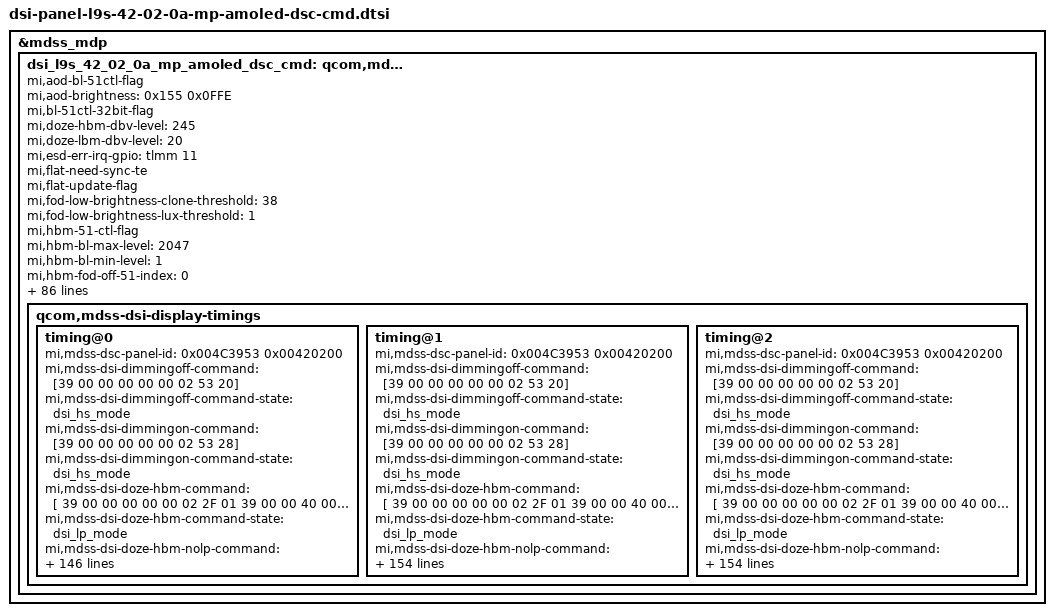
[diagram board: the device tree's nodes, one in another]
&mdss_mdp {
	dsi_l9s_42_02_0a_mp_amoled_dsc_cmd: 			qcom,mdss_dsi_l9s_42_02_0a_mp_amoled_dsc_cmd {
				mi,aod-bl-51ctl-flag;
				mi,aod-brightness = <0x155 0xffe>;
				mi,bl-51ctl-32bit-flag;
				mi,doze-hbm-dbv-level = <0xf5>;
				mi,doze-lbm-dbv-level = <0x14>;
				mi,esd-err-irq-gpio = <0xffffffff 0xb 0x2008>;
				mi,flat-need-sync-te;
				mi,flat-update-flag;
				mi,fod-low-brightness-clone-threshold = <0x26>;
				mi,fod-low-brightness-lux-threshold = <0x1>;
				mi,hbm-51-ctl-flag;
				mi,hbm-bl-max-level = <0x7ff>;
				mi,hbm-bl-min-level = <0x1>;
				mi,hbm-fod-off-51-index = <0x0>;
				mi,hbm-off-51-index = <0x0>;
				mi,local-hbm-alpha-ctrl-aa-area;
				mi,local-hbm-enabled;
				mi,local-hbm-green-500nit-update-flag;
				mi,local-hbm-white-1000nit-update-flag;
				mi,local-hbm-white-110nit-update-flag;
				mi,max-brightness-clone = <0xfff>;
				mi,mdss-dsi-fac-bl-max-level = <0x7ff>;
				mi,mdss-dsi-panel-dc-type = <0x0>;
				mi,mdss-fac-brightness-max-level = <0x7ff>;
				mi,need-fod-animal-in-normal-enabled;
				mi,panel-aod-to-off-command-need-enabled;
				mi,panel-id = <0x4c3953 0x420200>;
				mi,panel-on-dimming-delay = <0x78>;
				mi,thermal-dimming-flag;
				phandle = <0xa1>;
				qcom,bl-update-flag = "delay_until_first_frame";
				qcom,dsi-ctrl-num = <0x0>;
				qcom,dsi-phy-num = <0x0>;
				qcom,dsi-select-clocks = "pll_byte_clk0", "pll_dsi_clk0";
				qcom,esd-aod-check-enabled;
				qcom,esd-check-enabled;
				qcom,mdss-brightness-init-level = <0x133>;
				qcom,mdss-brightness-max-level = <0xfff>;
				qcom,mdss-dsi-bl-inverted-dbv;
				qcom,mdss-dsi-bl-max-level = <0xfff>;
				qcom,mdss-dsi-bl-min-level = <0x3>;
				qcom,mdss-dsi-bl-pmic-control-type = "bl_ctrl_dcs";
				qcom,mdss-dsi-bllp-eof-power-mode;
				qcom,mdss-dsi-bllp-power-mode;
				qcom,mdss-dsi-border-color = <0x0>;
				qcom,mdss-dsi-bpp = <0x1e>;
				qcom,mdss-dsi-clk-strength = <0xff>;
				qcom,mdss-dsi-color-order = "rgb_swap_rgb";
				qcom,mdss-dsi-dma-schedule-line = <0x1>;
				qcom,mdss-dsi-dma-schedule-window = <0x32>;
				qcom,mdss-dsi-dma-trigger = "trigger_sw";
				qcom,mdss-dsi-factory-bl-max-level = <0x7ff>;
				qcom,mdss-dsi-lane-0-state;
				qcom,mdss-dsi-lane-1-state;
				qcom,mdss-dsi-lane-2-state;
				qcom,mdss-dsi-lane-3-state;
				qcom,mdss-dsi-lane-map = "lane_map_0123";
				qcom,mdss-dsi-lp11-init;
				qcom,mdss-dsi-mdp-trigger = "none";
				qcom,mdss-dsi-panel-blackness-level = <0xc9e>;
				qcom,mdss-dsi-panel-hdr-color-primaries = <0x38a4 0x3c8c 0x7d00 0x4268 0x3c8c 0x7530 0x1f40 0xbb8>;
				qcom,mdss-dsi-panel-hdr-enabled;
				qcom,mdss-dsi-panel-mode-switch;
				qcom,mdss-dsi-panel-name = "xiaomi 42 02 0a cmd mode dsc dsi panel";
				qcom,mdss-dsi-panel-peak-brightness = <0x401640>;
				qcom,mdss-dsi-panel-status-check-mode = "reg_read";
				qcom,mdss-dsi-panel-status-command = <0x6010000 0x1fa>;
				qcom,mdss-dsi-panel-status-command-state = "dsi_lp_mode";
				qcom,mdss-dsi-panel-status-offset-command = [39 01 00 00 00 00 05 ff aa 55 a5 81 15 01 00 00 00 00 02 6f 0f];
				qcom,mdss-dsi-panel-status-offset-command-state = "dsi_lp_mode";
				qcom,mdss-dsi-panel-status-read-length = <0x1>;
				qcom,mdss-dsi-panel-status-value = <0x0>;
				qcom,mdss-dsi-panel-type = "dsi_cmd_mode";
				qcom,mdss-dsi-reset-sequence = <0x1 0xb 0x0 0x1 0x1 0xb>;
				qcom,mdss-dsi-stream = <0x0>;
				qcom,mdss-dsi-te-check-enable;
				qcom,mdss-dsi-te-dcs-command = <0x1>;
				qcom,mdss-dsi-te-pin-select = <0x1>;
				qcom,mdss-dsi-te-using-te-pin;
				qcom,mdss-dsi-traffic-mode = "burst_mode";
				qcom,mdss-dsi-tx-eot-append;
				qcom,mdss-dsi-underflow-color = <0xff>;
				qcom,mdss-dsi-virtual-channel-id = <0x0>;
				qcom,mdss-dsi-wr-mem-continue = <0x3c>;
				qcom,mdss-dsi-wr-mem-start = <0x2c>;
				qcom,mdss-factory-brightness-max-level = <0x7ff>;
				qcom,mdss-pan-physical-height-dimension = <0x5ed>;
				qcom,mdss-pan-physical-width-dimension = <0x2ab>;
				qcom,panel-supply-entries = <0x8b>;
				qcom,platform-reset-gpio = <0xffffffff 0x2a 0x0>;
				qcom,platform-te-gpio = <0xffffffff 0x52 0x0>;

				qcom,mdss-dsi-display-timings {

					timing@0 {
						mi,mdss-dsc-panel-id = <0x4c3953 0x420200>;
						mi,mdss-dsi-dimmingoff-command = [39 00 00 00 00 00 02 53 20];
						mi,mdss-dsi-dimmingoff-command-state = "dsi_hs_mode";
						mi,mdss-dsi-dimmingon-command = [39 00 00 00 00 00 02 53 28];
						mi,mdss-dsi-dimmingon-command-state = "dsi_hs_mode";
						mi,mdss-dsi-doze-hbm-command = [39 00 00 00 00 00 02 2f 01 39 00 00 40 00 00 02 26 01 39 00 00 40 00 00 06 f0 55 aa 52 08 00 39 00 00 40 00 00 02 b2 08 39 00 00 40 00 00 05 51 00 f5 0f fe 39 00 00 00 00 00 02 39 00];
						mi,mdss-dsi-doze-hbm-command-state = "dsi_lp_mode";
						mi,mdss-dsi-doze-hbm-nolp-command = [39 00 00 00 00 00 06 f0 55 aa 52 08 00 39 00 00 40 00 00 02 b2 18 39 00 00 40 00 00 05 51 00 f5 0f fe 39 00 00 00 00 00 02 38 00];
						mi,mdss-dsi-doze-hbm-nolp-command-state = "dsi_lp_mode";
						mi,mdss-dsi-doze-lbm-command = [39 00 00 00 00 00 02 2f 01 39 00 00 40 00 00 02 26 01 39 00 00 40 00 00 06 f0 55 aa 52 08 00 39 00 00 40 00 00 02 b2 08 39 00 00 40 00 00 05 51 00 14 01 55 39 00 00 00 00 00 02 39 00];
						mi,mdss-dsi-doze-lbm-command-state = "dsi_lp_mode";
						mi,mdss-dsi-doze-lbm-nolp-command = [39 00 00 00 00 00 06 f0 55 aa 52 08 00 39 00 00 40 00 00 02 b2 18 39 00 00 40 00 00 05 51 00 14 01 55 39 00 00 00 00 00 02 38 00];
						mi,mdss-dsi-doze-lbm-nolp-command-state = "dsi_lp_mode";
						mi,mdss-dsi-flat-mode-off-command = <0x39000000 0x22f 0x1390000 0x40000002 0x26013900 0x400000 0x6f055aa 0x52080839 0x4000 0x26f07 0x39000020 0x5b9 0x18>;
						mi,mdss-dsi-flat-mode-off-command-state = "dsi_lp_mode";
						mi,mdss-dsi-flat-mode-off-command-update = <0xb9 0x4 0x4>;
						mi,mdss-dsi-flat-mode-off-read-pre-command = [39 00 00 00 00 00 06 f0 55 aa 52 08 00 39 00 00 00 00 00 02 6f 48];
						mi,mdss-dsi-flat-mode-off-read-pre-command-state = "dsi_lp_mode";
						mi,mdss-dsi-flat-mode-on-command = <0x39000000 0x22f 0x1390000 0x40000002 0x26043900 0x400000 0x6f055aa 0x52080839 0x4000 0x26f07 0x39000020 0x5b9 0x0>;
						mi,mdss-dsi-flat-mode-on-command-state = "dsi_lp_mode";
						mi,mdss-dsi-flat-mode-on-command-update = <0xb9 0x4 0x4>;
						mi,mdss-dsi-flat-mode-read-pre-command = [39 00 00 00 00 00 06 f0 55 aa 52 08 00 39 00 00 00 00 00 02 6f 3f];
						mi,mdss-dsi-flat-mode-read-pre-command-state = "dsi_lp_mode";
						mi,mdss-dsi-hbm-off-command = <0x39000000 0x551 0x7ff0000>;
						mi,mdss-dsi-hbm-off-command-state = "dsi_lp_mode";
						mi,mdss-dsi-hbm-on-command = <0x39000000 0x551 0xfff0000>;
						mi,mdss-dsi-hbm-on-command-state = "dsi_lp_mode";
						mi,mdss-dsi-local-hbm-hlpm-white-1000nit-command = [39 00 00 00 00 00 06 f0 55 aa 52 08 00 39 00 00 40 00 00 02 b2 18 39 00 00 40 00 00 02 38 00 39 00 00 40 00 00 06 f0 55 aa 52 08 00 39 00 00 40 00 00 02 6f 29 39 00 00 40 00 00 02 d9 00 39 00 00 40 00 00 02 6f 01 39 00 00 40 00 00 02 d9 80 39 00 00 40 00 00 02 6f 07 39 00 00 40 00 00 03 b2 07 ff 39 00 00 40 00 00 02 6f 17 39 00 00 40 00 00 03 b2 07 ff 39 00 00 40 00 00 02 6f 1f 39 00 00 40 00 00 03 b2 00 50 39 00 00 40 00 00 06 f0 55 aa 52 08 02 39 00 00 40 00 00 02 6f 08 39 00 00 40 00 00 07 d0 0b 07 09 7b 0c 1d 39 00 00 40 00 00 06 f0 55 aa 52 08 07 39 00 00 40 00 00 02 c0 05 39 00 00 40 00 00 02 53 20 39 00 00 40 00 00 05 88 02 1c 08 73 39 00 00 40 00 00 03 51 07 ff 39 00 00 40 00 00 03 87 04 4e 39 00 00 40 00 00 02 6f 02 39 00 00 00 30 00 02 87 05];
						mi,mdss-dsi-local-hbm-hlpm-white-1000nit-command-state = "dsi_hs_mode";
						mi,mdss-dsi-local-hbm-hlpm-white-1000nit-command-update = <0x87 0x16 0x2 0xd0 0x10 0x6>;
						mi,mdss-dsi-local-hbm-hlpm-white-110nit-command = [39 00 00 00 00 00 06 f0 55 aa 52 08 00 39 00 00 40 00 00 02 b2 18 39 00 00 40 00 00 02 38 00 39 00 00 40 00 00 06 f0 55 aa 52 08 00 39 00 00 40 00 00 02 6f 29 39 00 00 40 00 00 02 d9 00 39 00 00 40 00 00 02 6f 01 39 00 00 40 00 00 02 d9 80 39 00 00 40 00 00 02 6f 07 39 00 00 40 00 00 03 b2 07 ff 39 00 00 40 00 00 02 6f 17 39 00 00 40 00 00 03 b2 07 ff 39 00 00 40 00 00 02 6f 1f 39 00 00 40 00 00 03 b2 00 50 39 00 00 40 00 00 06 f0 55 aa 52 08 02 39 00 00 40 00 00 02 6f 08 39 00 00 40 00 00 07 d0 0b 07 09 7b 0c 1d 39 00 00 40 00 00 06 f0 55 aa 52 08 07 39 00 00 40 00 00 02 c0 05 39 00 00 40 00 00 02 53 20 39 00 00 40 00 00 05 88 02 1c 08 73 39 00 00 40 00 00 03 51 07 ff 39 00 00 40 00 00 03 87 04 4e 39 00 00 40 00 00 02 6f 02 39 00 00 00 30 00 02 87 05];
						mi,mdss-dsi-local-hbm-hlpm-white-110nit-command-state = "dsi_hs_mode";
						mi,mdss-dsi-local-hbm-hlpm-white-110nit-command-update = <0x87 0x16 0x2 0xd0 0x10 0x6>;
						mi,mdss-dsi-local-hbm-normal-green-500nit-command = [39 00 00 00 00 00 06 f0 55 aa 52 08 00 39 00 00 40 00 00 02 6f 29 39 00 00 40 00 00 02 d9 00 39 00 00 40 00 00 02 6f 01 39 00 00 40 00 00 02 d9 80 39 00 00 40 00 00 02 6f 07 39 00 00 40 00 00 03 b2 07 ff 39 00 00 40 00 00 02 6f 17 39 00 00 40 00 00 03 b2 07 ff 39 00 00 40 00 00 02 6f 1f 39 00 00 40 00 00 03 b2 00 50 39 00 00 40 00 00 06 f0 55 aa 52 08 02 39 00 00 40 00 00 02 6f 08 39 00 00 40 00 00 07 d0 00 00 09 40 00 00 39 00 00 40 00 00 06 f0 55 aa 52 08 07 39 00 00 40 00 00 02 c0 05 39 00 00 40 00 00 02 53 20 39 00 00 40 00 00 05 88 02 1c 08 73 39 00 00 40 00 00 03 51 07 ff 39 00 00 40 00 00 03 87 04 4e 39 00 00 40 00 00 02 6f 02 39 00 00 00 30 00 02 87 05];
						mi,mdss-dsi-local-hbm-normal-green-500nit-command-state = "dsi_hs_mode";
						mi,mdss-dsi-local-hbm-normal-green-500nit-command-update = <0x87 0x13 0x2 0xd0 0xd 0x6>;
						mi,mdss-dsi-local-hbm-normal-white-1000nit-command = [39 00 00 00 00 00 06 f0 55 aa 52 08 00 39 00 00 40 00 00 02 6f 29 39 00 00 40 00 00 02 d9 00 39 00 00 40 00 00 02 6f 01 39 00 00 40 00 00 02 d9 80 39 00 00 40 00 00 02 6f 07 39 00 00 40 00 00 03 b2 07 ff 39 00 00 40 00 00 02 6f 17 39 00 00 40 00 00 03 b2 07 ff 39 00 00 40 00 00 02 6f 1f 39 00 00 40 00 00 03 b2 00 50 39 00 00 40 00 00 06 f0 55 aa 52 08 02 39 00 00 40 00 00 02 6f 08 39 00 00 40 00 00 07 d0 0b 07 09 7b 0c 1d 39 00 00 40 00 00 06 f0 55 aa 52 08 07 39 00 00 40 00 00 02 c0 05 39 00 00 40 00 00 02 53 20 39 00 00 40 00 00 05 88 02 1c 08 73 39 00 00 40 00 00 03 51 07 ff 39 00 00 40 00 00 03 87 04 4e 39 00 00 40 00 00 02 6f 02 39 00 00 00 30 00 02 87 05];
						mi,mdss-dsi-local-hbm-normal-white-1000nit-command-state = "dsi_hs_mode";
						mi,mdss-dsi-local-hbm-normal-white-1000nit-command-update = <0x87 0x13 0x2 0xd0 0xd 0x6>;
						mi,mdss-dsi-local-hbm-normal-white-110nit-command = [39 00 00 00 00 00 06 f0 55 aa 52 08 00 39 00 00 40 00 00 02 6f 29 39 00 00 40 00 00 02 d9 00 39 00 00 40 00 00 02 6f 01 39 00 00 40 00 00 02 d9 80 39 00 00 40 00 00 02 6f 07 39 00 00 40 00 00 03 b2 07 ff 39 00 00 40 00 00 02 6f 17 39 00 00 40 00 00 03 b2 07 ff 39 00 00 40 00 00 02 6f 1f 39 00 00 40 00 00 03 b2 00 50 39 00 00 40 00 00 06 f0 55 aa 52 08 02 39 00 00 40 00 00 02 6f 08 39 00 00 40 00 00 07 d0 0b 07 09 7b 0c 1d 39 00 00 40 00 00 06 f0 55 aa 52 08 07 39 00 00 40 00 00 02 c0 05 39 00 00 40 00 00 02 53 20 39 00 00 40 00 00 05 88 02 1c 08 73 39 00 00 40 00 00 03 51 07 ff 39 00 00 40 00 00 03 87 04 4e 39 00 00 40 00 00 02 6f 02 39 00 00 00 30 00 02 87 05];
						mi,mdss-dsi-local-hbm-normal-white-110nit-command-state = "dsi_hs_mode";
						mi,mdss-dsi-local-hbm-normal-white-110nit-command-update = <0x87 0x13 0x2 0xd0 0xd 0x6>;
						mi,mdss-dsi-local-hbm-off-to-hbm-command = [39 00 00 00 00 00 02 53 20 39 00 00 40 00 00 03 51 00 00 39 00 00 40 00 00 02 6f 02 39 00 00 00 00 00 02 87 04];
						mi,mdss-dsi-local-hbm-off-to-hbm-command-state = "dsi_hs_mode";
						mi,mdss-dsi-local-hbm-off-to-hbm-command-update = <0x51 0x1 0x2>;
						mi,mdss-dsi-local-hbm-off-to-hlpm-command = [39 00 00 00 00 00 02 53 20 39 00 00 40 00 00 03 51 00 00 39 00 00 40 00 00 02 6f 02 39 00 00 40 00 00 02 87 04 39 00 00 40 00 00 02 2f 01 39 00 00 40 00 00 02 26 01 39 00 00 40 00 00 06 f0 55 aa 52 08 00 39 00 00 40 00 00 02 b2 08 39 00 00 40 00 00 05 51 00 f5 0f ff 39 00 00 00 00 00 02 39 00];
						mi,mdss-dsi-local-hbm-off-to-hlpm-command-state = "dsi_hs_mode";
						mi,mdss-dsi-local-hbm-off-to-llpm-command = [39 00 00 00 00 00 02 53 20 39 00 00 40 00 00 03 51 00 00 39 00 00 40 00 00 02 6f 02 39 00 00 40 00 00 02 87 04 39 00 00 40 00 00 02 2f 01 39 00 00 40 00 00 02 26 01 39 00 00 40 00 00 06 f0 55 aa 52 08 00 39 00 00 40 00 00 02 b2 08 39 00 00 40 00 00 05 51 00 14 01 55 39 00 00 00 00 00 02 39 00];
						mi,mdss-dsi-local-hbm-off-to-llpm-command-state = "dsi_hs_mode";
						mi,mdss-dsi-local-hbm-off-to-normal-command = [39 00 00 00 00 00 02 53 20 39 00 00 40 00 00 03 51 00 00 39 00 00 40 00 00 02 6f 02 39 00 00 00 00 00 02 87 04];
						mi,mdss-dsi-local-hbm-off-to-normal-command-state = "dsi_hs_mode";
						mi,mdss-dsi-local-hbm-off-to-normal-command-update = <0x51 0x1 0x2>;
						mi,mdss-dsi-pre-doze-to-off-command = [39 01 00 00 00 00 06 f0 55 aa 52 08 01 39 01 00 00 00 00 02 ce 0c];
						mi,mdss-dsi-pre-doze-to-off-command-state = "dsi_hs_mode";
						mi,mdss-dsi-switch-page-command = [39 00 00 00 00 00 06 f0 55 aa 52 08 00];
						mi,mdss-dsi-switch-page-command-state = "dsi_lp_mode";
						mi,mdss-dsi-switch-page-command-update = <0xf0 0x0 0x5>;
						mi,mdss-flat-status-control-gamma-cfg = <0x4 0x1>;
						qcom,compression-mode = "dsc";
						qcom,default-topology-index = <0x0>;
						qcom,display-topology = <0x1 0x1 0x1>;
						qcom,mdss-dsc-bit-per-component = <0xa>;
						qcom,mdss-dsc-bit-per-pixel = <0x8>;
						qcom,mdss-dsc-block-prediction-enable;
						qcom,mdss-dsc-scr-version = <0x0>;
						qcom,mdss-dsc-slice-height = <0xc>;
						qcom,mdss-dsc-slice-per-pkt = <0x1>;
						qcom,mdss-dsc-slice-width = <0x438>;
						qcom,mdss-dsc-version = <0x11>;
						qcom,mdss-dsi-cmd-mode;
						qcom,mdss-dsi-h-back-porch = <0x40>;
						qcom,mdss-dsi-h-front-porch = <0x20>;
						qcom,mdss-dsi-h-left-border = <0x0>;
						qcom,mdss-dsi-h-pulse-width = <0x40>;
						qcom,mdss-dsi-h-right-border = <0x0>;
						qcom,mdss-dsi-h-sync-pulse = <0x0>;
						qcom,mdss-dsi-h-sync-skew = <0x0>;
						qcom,mdss-dsi-nolp-command = [39 00 00 00 00 00 06 f0 55 aa 52 08 00 39 00 00 40 00 00 02 b2 18 39 00 00 00 32 00 02 38 00];
						qcom,mdss-dsi-nolp-command-state = "dsi_hs_mode";
						qcom,mdss-dsi-off-command = [39 00 00 00 0a 00 02 28 00 39 00 00 00 78 00 02 10 00];
						qcom,mdss-dsi-off-command-state = "dsi_lp_mode";
						qcom,mdss-dsi-on-command = [39 00 00 00 00 00 06 f0 55 aa 52 08 00 39 00 00 40 00 00 02 6f 08 39 00 00 40 00 00 09 ba 01 b1 00 0a 00 16 00 00 39 00 00 40 00 00 06 f0 55 aa 52 08 04 39 00 00 40 00 00 02 b1 02 39 00 00 40 00 00 05 3b 00 14 00 0c 39 00 00 40 00 00 02 90 01 39 00 00 40 00 00 13 91 ab 28 00 0c c2 00 03 1c 01 7e 00 0f 08 bb 04 3d 10 f0 39 00 00 40 00 00 02 03 01 39 00 00 40 00 00 02 2c 00 39 00 00 40 00 00 06 f0 55 aa 52 08 07 39 00 00 40 00 00 02 c0 05 39 00 00 40 00 00 02 c1 00 39 00 00 40 00 00 02 c2 00 39 00 00 40 00 00 02 c3 00 39 00 00 40 00 00 02 c4 00 39 00 00 40 00 00 02 c5 00 39 00 00 40 00 00 02 c6 00 39 00 00 40 00 00 02 c7 00 39 00 00 40 00 00 02 c8 00 39 00 00 40 00 00 02 cd 00 39 00 00 40 00 00 02 ce 00 39 00 00 40 00 00 02 cf 00 39 00 00 40 00 00 02 d0 00 39 00 00 40 00 00 02 53 20 39 00 00 40 00 00 06 f0 55 aa 52 08 00 39 00 00 40 00 00 02 6f 02 39 00 00 40 00 00 03 b2 08 08 39 00 00 40 00 00 02 35 00 39 00 00 40 00 00 06 f0 55 aa 52 08 01 39 00 00 40 00 00 08 c3 94 01 8c d0 22 02 00 39 00 00 40 00 00 05 2a 00 00 04 37 39 00 00 40 00 00 05 2b 00 00 09 5f 39 00 00 40 00 00 02 2f 01 39 00 00 40 00 00 02 26 01 39 00 00 40 00 00 06 f0 55 aa 52 08 00 39 00 00 40 00 00 02 6f 05 39 00 00 00 00 00 02 be 88 39 00 00 40 00 00 05 ff aa 55 a5 80 39 00 00 40 00 00 02 6f 61 39 00 00 40 00 00 02 f3 80 39 00 00 40 00 00 06 f0 55 aa 52 08 01 39 00 00 40 00 00 02 6f 01 39 00 00 40 00 00 04 d2 00 00 11 39 00 00 40 00 00 02 6f 06 39 00 00 40 00 00 02 d2 05 39 00 00 40 00 00 02 6f 0f 39 00 00 40 00 00 02 d2 00 39 00 00 40 00 00 02 6f 09 39 00 00 00 00 00 03 d2 00 00 39 00 00 40 00 00 06 f0 55 aa 52 08 00 39 00 00 40 00 00 02 6f 01 39 00 00 40 00 00 02 c0 b3 39 00 00 40 00 00 05 ff aa 55 a5 80 39 00 00 40 00 00 02 6f 2e 39 00 00 40 00 00 02 fb d1 39 00 00 40 00 00 06 f0 55 aa 52 08 04 39 00 00 40 00 00 02 6f 0d 39 00 00 00 00 00 02 ca 05 39 00 00 40 00 00 06 f0 55 aa 52 08 07 39 00 00 40 00 00 02 c0 05 39 00 00 40 00 00 02 6f 00 39 00 00 40 00 00 16 c9 21 00 21 c9 21 10 00 00 3f e7 b7 88 3f e7 fa 60 80 04 5d 05 90 39 00 00 40 00 00 02 6f 15 39 00 00 40 00 00 10 c9 81 c0 16 82 1c 73 33 a0 21 6c 0f a3 a4 00 00 39 00 00 40 00 00 02 6f 24 39 00 00 40 00 00 08 c9 00 00 00 00 00 00 00 39 00 00 40 00 00 02 6f 00 39 00 00 40 00 00 16 ca 27 00 21 c9 21 10 00 00 00 00 00 00 3f e7 fa 60 80 00 00 00 00 39 00 00 40 00 00 02 6f 15 39 00 00 40 00 00 10 ca 82 1d 16 82 79 73 33 a0 00 00 03 5d a4 00 00 39 00 00 40 00 00 02 6f 24 39 00 00 40 00 00 08 ca 00 00 00 00 00 00 00 39 00 00 40 00 00 02 6f 00 39 00 00 40 00 00 16 cb 2d 00 21 10 21 10 00 00 3f e8 3c 80 80 00 00 00 00 00 00 00 00 39 00 00 40 00 00 02 6f 15 39 00 00 40 00 00 10 cb 81 c0 74 82 1c d0 33 10 00 00 0c a4 5c 00 00 39 00 00 40 00 00 02 6f 24 39 00 00 40 00 00 08 cb 00 00 00 00 00 00 00 39 00 00 40 00 00 02 6f 00 39 00 00 40 00 00 16 cc 2b 00 21 10 21 10 00 00 00 00 00 00 80 00 00 00 7f fb ba df 00 39 00 00 40 00 00 02 6f 15 39 00 00 40 00 00 10 cc 82 1d 74 82 79 d0 33 1f de f0 00 5c 5c 00 00 39 00 00 40 00 00 02 6f 24 39 00 00 00 00 00 08 cc 00 00 00 00 00 00 00 39 00 00 40 00 00 06 f0 55 aa 52 08 01 39 00 00 00 00 00 07 b7 20 20 20 20 20 20 39 00 00 00 50 00 02 11 00 39 00 00 00 00 00 02 29 00];
						qcom,mdss-dsi-on-command-state = "dsi_lp_mode";
						qcom,mdss-dsi-panel-clockrate = <0x31880dc0>;
						qcom,mdss-dsi-panel-framerate = <0x3c>;
						qcom,mdss-dsi-panel-height = <0x960>;
						qcom,mdss-dsi-panel-jitter = <0x5 0x1>;
						qcom,mdss-dsi-panel-phy-timings = [00 1d 07 07 17 22 07 07 08 02 04 00 19 0c];
						qcom,mdss-dsi-panel-width = <0x438>;
						qcom,mdss-dsi-timing-switch-command = <0x39000000 0x6f0 0x55aa5208 0x2390000 0x40000002 0xcc003900 0x400000 0x22f0139 0x0 0x22601>;
						qcom,mdss-dsi-timing-switch-command-state = "dsi_hs_mode";
						qcom,mdss-dsi-timing-switch-command-update = <0x26 0x3 0x1>;
						qcom,mdss-dsi-v-back-porch = <0x254>;
						qcom,mdss-dsi-v-bottom-border = <0x0>;
						qcom,mdss-dsi-v-front-porch = <0x3e8>;
						qcom,mdss-dsi-v-pulse-width = <0x7e>;
						qcom,mdss-dsi-v-top-border = <0x0>;
						qcom,mdss-mdp-transfer-time-us = <0x36b0>;
					};

					timing@1 {
						mi,mdss-dsc-panel-id = <0x4c3953 0x420200>;
						mi,mdss-dsi-dimmingoff-command = [39 00 00 00 00 00 02 53 20];
						mi,mdss-dsi-dimmingoff-command-state = "dsi_hs_mode";
						mi,mdss-dsi-dimmingon-command = [39 00 00 00 00 00 02 53 28];
						mi,mdss-dsi-dimmingon-command-state = "dsi_hs_mode";
						mi,mdss-dsi-doze-hbm-command = [39 00 00 00 00 00 02 2f 01 39 00 00 40 00 00 02 26 01 39 00 00 40 00 00 06 f0 55 aa 52 08 00 39 00 00 40 00 00 02 b2 08 39 00 00 40 00 00 05 51 00 f5 0f fe 39 00 00 00 00 00 02 39 00];
						mi,mdss-dsi-doze-hbm-command-state = "dsi_lp_mode";
						mi,mdss-dsi-doze-hbm-nolp-command = <0x39000000 0x6f0 0x55aa5208 0x390000 0x40000002 0xb2183900 0x400000 0x55100f5 0xffe3900 0x0 0x2380039 0x0 0x22f02>;
						mi,mdss-dsi-doze-hbm-nolp-command-state = "dsi_lp_mode";
						mi,mdss-dsi-doze-lbm-command = [39 00 00 00 00 00 02 2f 01 39 00 00 40 00 00 02 26 01 39 00 00 40 00 00 06 f0 55 aa 52 08 00 39 00 00 40 00 00 02 b2 08 39 00 00 40 00 00 05 51 00 14 01 55 39 00 00 00 00 00 02 39 00];
						mi,mdss-dsi-doze-lbm-command-state = "dsi_lp_mode";
						mi,mdss-dsi-doze-lbm-nolp-command = <0x39000000 0x6f0 0x55aa5208 0x390000 0x40000002 0xb2183900 0x400000 0x5510014 0x1553900 0x0 0x2380039 0x0 0x22f02>;
						mi,mdss-dsi-doze-lbm-nolp-command-state = "dsi_lp_mode";
						mi,mdss-dsi-flat-mode-off-command = [39 00 00 00 00 00 02 2f 02 39 00 00 40 00 00 06 f0 55 aa 52 08 00 39 00 00 40 00 00 02 6f 09 39 00 00 40 00 00 02 c0 20 39 00 00 40 00 00 06 f0 55 aa 52 08 02 39 00 00 40 00 00 02 cc 30 39 00 00 40 00 00 02 ce 01 39 00 00 40 00 00 06 f0 55 aa 52 08 08 39 00 00 40 00 00 02 6f 07 39 00 00 20 14 00 05 b9 00 00 00 18];
						mi,mdss-dsi-flat-mode-off-command-state = "dsi_hs_mode";
						mi,mdss-dsi-flat-mode-off-command-update = <0xb9 0x9 0x4>;
						mi,mdss-dsi-flat-mode-off-read-pre-command = [39 00 00 00 00 00 06 f0 55 aa 52 08 00 39 00 00 00 00 00 02 6f 48];
						mi,mdss-dsi-flat-mode-off-read-pre-command-state = "dsi_lp_mode";
						mi,mdss-dsi-flat-mode-off-sec-command = [39 00 00 00 00 00 06 f0 55 aa 52 08 02 39 00 00 00 00 00 02 cc 00];
						mi,mdss-dsi-flat-mode-off-sec-command-state = "dsi_lp_mode";
						mi,mdss-dsi-flat-mode-on-command = [39 00 00 00 00 00 02 2f 02 39 00 00 40 00 00 06 f0 55 aa 52 08 00 39 00 00 40 00 00 02 6f 09 39 00 00 40 00 00 02 c0 60 39 00 00 40 00 00 06 f0 55 aa 52 08 02 39 00 00 40 00 00 02 cc 30 39 00 00 40 00 00 02 ce 01 39 00 00 40 00 00 06 f0 55 aa 52 08 08 39 00 00 40 00 00 02 6f 07 39 00 00 20 14 00 05 b9 00 00 00 00];
						mi,mdss-dsi-flat-mode-on-command-state = "dsi_hs_mode";
						mi,mdss-dsi-flat-mode-on-command-update = <0xb9 0x9 0x4>;
						mi,mdss-dsi-flat-mode-on-sec-command = [39 00 00 00 00 00 06 f0 55 aa 52 08 02 39 00 00 00 00 00 02 cc 00];
						mi,mdss-dsi-flat-mode-on-sec-command-state = "dsi_lp_mode";
						mi,mdss-dsi-flat-mode-read-pre-command = [39 00 00 00 00 00 06 f0 55 aa 52 08 00 39 00 00 00 00 00 02 6f 3f];
						mi,mdss-dsi-flat-mode-read-pre-command-state = "dsi_lp_mode";
						mi,mdss-dsi-hbm-off-command = <0x39000000 0x551 0x7ff0000>;
						mi,mdss-dsi-hbm-off-command-state = "dsi_lp_mode";
						mi,mdss-dsi-hbm-on-command = <0x39000000 0x551 0xfff0000>;
						mi,mdss-dsi-hbm-on-command-state = "dsi_lp_mode";
						mi,mdss-dsi-local-hbm-hlpm-white-1000nit-command = [39 00 00 00 00 00 06 f0 55 aa 52 08 00 39 00 00 40 00 00 02 b2 18 39 00 00 40 00 00 02 38 00 39 00 00 00 00 00 02 2f 02 39 00 00 40 00 00 06 f0 55 aa 52 08 00 39 00 00 40 00 00 02 6f 29 39 00 00 40 00 00 02 d9 00 39 00 00 40 00 00 02 6f 01 39 00 00 40 00 00 02 d9 80 39 00 00 40 00 00 02 6f 07 39 00 00 40 00 00 03 b2 07 ff 39 00 00 40 00 00 02 6f 17 39 00 00 40 00 00 03 b2 07 ff 39 00 00 40 00 00 02 6f 1f 39 00 00 40 00 00 03 b2 00 50 39 00 00 40 00 00 06 f0 55 aa 52 08 02 39 00 00 40 00 00 02 6f 08 39 00 00 40 00 00 07 d0 0b 07 09 7b 0c 1d 39 00 00 40 00 00 06 f0 55 aa 52 08 07 39 00 00 40 00 00 02 c0 05 39 00 00 40 00 00 02 53 20 39 00 00 40 00 00 05 88 02 1c 08 73 39 00 00 40 00 00 03 51 07 ff 39 00 00 40 00 00 03 87 04 4e 39 00 00 40 00 00 02 6f 02 39 00 00 00 30 00 02 87 05];
						mi,mdss-dsi-local-hbm-hlpm-white-1000nit-command-state = "dsi_hs_mode";
						mi,mdss-dsi-local-hbm-hlpm-white-1000nit-command-update = <0x87 0x17 0x2 0xd0 0x11 0x6>;
						mi,mdss-dsi-local-hbm-hlpm-white-110nit-command = [39 00 00 00 00 00 06 f0 55 aa 52 08 00 39 00 00 40 00 00 02 b2 18 39 00 00 40 00 00 02 38 00 39 00 00 00 00 00 02 2f 02 39 00 00 40 00 00 06 f0 55 aa 52 08 00 39 00 00 40 00 00 02 6f 29 39 00 00 40 00 00 02 d9 00 39 00 00 40 00 00 02 6f 01 39 00 00 40 00 00 02 d9 80 39 00 00 40 00 00 02 6f 07 39 00 00 40 00 00 03 b2 07 ff 39 00 00 40 00 00 02 6f 17 39 00 00 40 00 00 03 b2 07 ff 39 00 00 40 00 00 02 6f 1f 39 00 00 40 00 00 03 b2 00 50 39 00 00 40 00 00 06 f0 55 aa 52 08 02 39 00 00 40 00 00 02 6f 08 39 00 00 40 00 00 07 d0 0b 07 09 7b 0c 1d 39 00 00 40 00 00 06 f0 55 aa 52 08 07 39 00 00 40 00 00 02 c0 05 39 00 00 40 00 00 02 53 20 39 00 00 40 00 00 05 88 02 1c 08 73 39 00 00 40 00 00 03 51 07 ff 39 00 00 40 00 00 03 87 04 4e 39 00 00 40 00 00 02 6f 02 39 00 00 00 30 00 02 87 05];
						mi,mdss-dsi-local-hbm-hlpm-white-110nit-command-state = "dsi_hs_mode";
						mi,mdss-dsi-local-hbm-hlpm-white-110nit-command-update = <0x87 0x17 0x2 0xd0 0x11 0x6>;
						mi,mdss-dsi-local-hbm-normal-green-500nit-command = [39 00 00 00 00 00 06 f0 55 aa 52 08 00 39 00 00 40 00 00 02 6f 29 39 00 00 40 00 00 02 d9 00 39 00 00 40 00 00 02 6f 01 39 00 00 40 00 00 02 d9 80 39 00 00 40 00 00 02 6f 07 39 00 00 40 00 00 03 b2 07 ff 39 00 00 40 00 00 02 6f 17 39 00 00 40 00 00 03 b2 07 ff 39 00 00 40 00 00 02 6f 1f 39 00 00 40 00 00 03 b2 00 50 39 00 00 40 00 00 06 f0 55 aa 52 08 02 39 00 00 40 00 00 02 6f 08 39 00 00 40 00 00 07 d0 00 00 09 40 00 00 39 00 00 40 00 00 06 f0 55 aa 52 08 07 39 00 00 40 00 00 02 c0 05 39 00 00 40 00 00 02 53 20 39 00 00 40 00 00 05 88 02 1c 08 73 39 00 00 40 00 00 03 51 07 ff 39 00 00 40 00 00 03 87 04 4e 39 00 00 40 00 00 02 6f 02 39 00 00 00 30 00 02 87 05];
						mi,mdss-dsi-local-hbm-normal-green-500nit-command-state = "dsi_hs_mode";
						mi,mdss-dsi-local-hbm-normal-green-500nit-command-update = <0x87 0x13 0x2 0xd0 0xd 0x6>;
						mi,mdss-dsi-local-hbm-normal-white-1000nit-command = [39 00 00 00 00 00 06 f0 55 aa 52 08 00 39 00 00 40 00 00 02 6f 29 39 00 00 40 00 00 02 d9 00 39 00 00 40 00 00 02 6f 01 39 00 00 40 00 00 02 d9 80 39 00 00 40 00 00 02 6f 07 39 00 00 40 00 00 03 b2 07 ff 39 00 00 40 00 00 02 6f 17 39 00 00 40 00 00 03 b2 07 ff 39 00 00 40 00 00 02 6f 1f 39 00 00 40 00 00 03 b2 00 50 39 00 00 40 00 00 06 f0 55 aa 52 08 02 39 00 00 40 00 00 02 6f 08 39 00 00 40 00 00 07 d0 0b 07 09 7b 0c 1d 39 00 00 40 00 00 06 f0 55 aa 52 08 07 39 00 00 40 00 00 02 c0 05 39 00 00 40 00 00 02 53 20 39 00 00 40 00 00 05 88 02 1c 08 73 39 00 00 40 00 00 03 51 07 ff 39 00 00 40 00 00 03 87 04 4e 39 00 00 40 00 00 02 6f 02 39 00 00 00 30 00 02 87 05];
						mi,mdss-dsi-local-hbm-normal-white-1000nit-command-state = "dsi_hs_mode";
						mi,mdss-dsi-local-hbm-normal-white-1000nit-command-update = <0x87 0x13 0x2 0xd0 0xd 0x6>;
						mi,mdss-dsi-local-hbm-normal-white-110nit-command = [39 00 00 00 00 00 06 f0 55 aa 52 08 00 39 00 00 40 00 00 02 6f 29 39 00 00 40 00 00 02 d9 00 39 00 00 40 00 00 02 6f 01 39 00 00 40 00 00 02 d9 80 39 00 00 40 00 00 02 6f 07 39 00 00 40 00 00 03 b2 07 ff 39 00 00 40 00 00 02 6f 17 39 00 00 40 00 00 03 b2 07 ff 39 00 00 40 00 00 02 6f 1f 39 00 00 40 00 00 03 b2 00 50 39 00 00 40 00 00 06 f0 55 aa 52 08 02 39 00 00 40 00 00 02 6f 08 39 00 00 40 00 00 07 d0 0b 07 09 7b 0c 1d 39 00 00 40 00 00 06 f0 55 aa 52 08 07 39 00 00 40 00 00 02 c0 05 39 00 00 40 00 00 02 53 20 39 00 00 40 00 00 05 88 02 1c 08 73 39 00 00 40 00 00 03 51 07 ff 39 00 00 40 00 00 03 87 04 4e 39 00 00 40 00 00 02 6f 02 39 00 00 00 30 00 02 87 05];
						mi,mdss-dsi-local-hbm-normal-white-110nit-command-state = "dsi_hs_mode";
						mi,mdss-dsi-local-hbm-normal-white-110nit-command-update = <0x87 0x13 0x2 0xd0 0xd 0x6>;
						mi,mdss-dsi-local-hbm-off-to-hbm-command = [39 00 00 00 00 00 02 53 20 39 00 00 40 00 00 03 51 00 00 39 00 00 40 00 00 02 6f 02 39 00 00 00 00 00 02 87 04];
						mi,mdss-dsi-local-hbm-off-to-hbm-command-state = "dsi_hs_mode";
						mi,mdss-dsi-local-hbm-off-to-hbm-command-update = <0x51 0x1 0x2>;
						mi,mdss-dsi-local-hbm-off-to-hlpm-command = [39 00 00 00 00 00 02 53 20 39 00 00 40 00 00 03 51 00 00 39 00 00 40 00 00 02 6f 02 39 00 00 40 00 00 02 87 04 39 00 00 40 00 00 02 2f 01 39 00 00 40 00 00 02 26 01 39 00 00 40 00 00 06 f0 55 aa 52 08 00 39 00 00 40 00 00 02 b2 08 39 00 00 40 00 00 05 51 00 f5 0f ff 39 00 00 00 00 00 02 39 00];
						mi,mdss-dsi-local-hbm-off-to-hlpm-command-state = "dsi_hs_mode";
						mi,mdss-dsi-local-hbm-off-to-llpm-command = [39 00 00 00 00 00 02 53 20 39 00 00 40 00 00 03 51 00 00 39 00 00 40 00 00 02 6f 02 39 00 00 40 00 00 02 87 04 39 00 00 40 00 00 02 2f 01 39 00 00 40 00 00 02 26 01 39 00 00 40 00 00 06 f0 55 aa 52 08 00 39 00 00 40 00 00 02 b2 08 39 00 00 40 00 00 05 51 00 14 01 55 39 00 00 00 00 00 02 39 00];
						mi,mdss-dsi-local-hbm-off-to-llpm-command-state = "dsi_hs_mode";
						mi,mdss-dsi-local-hbm-off-to-normal-command = [39 00 00 00 00 00 02 53 20 39 00 00 40 00 00 03 51 00 00 39 00 00 40 00 00 02 6f 02 39 00 00 00 00 00 02 87 04];
						mi,mdss-dsi-local-hbm-off-to-normal-command-state = "dsi_hs_mode";
						mi,mdss-dsi-local-hbm-off-to-normal-command-update = <0x51 0x1 0x2>;
						mi,mdss-dsi-pre-doze-to-off-command = [39 01 00 00 00 00 06 f0 55 aa 52 08 01 39 01 00 00 00 00 02 ce 0c];
						mi,mdss-dsi-pre-doze-to-off-command-state = "dsi_hs_mode";
						mi,mdss-dsi-switch-page-command = [39 00 00 00 00 00 06 f0 55 aa 52 08 00];
						mi,mdss-dsi-switch-page-command-state = "dsi_lp_mode";
						mi,mdss-dsi-switch-page-command-update = <0xf0 0x0 0x5>;
						mi,mdss-flat-status-control-gamma-cfg = <0x60 0x20>;
						qcom,compression-mode = "dsc";
						qcom,default-topology-index = <0x0>;
						qcom,display-topology = <0x1 0x1 0x1>;
						qcom,mdss-dsc-bit-per-component = <0xa>;
						qcom,mdss-dsc-bit-per-pixel = <0x8>;
						qcom,mdss-dsc-block-prediction-enable;
						qcom,mdss-dsc-scr-version = <0x0>;
						qcom,mdss-dsc-slice-height = <0xc>;
						qcom,mdss-dsc-slice-per-pkt = <0x1>;
						qcom,mdss-dsc-slice-width = <0x438>;
						qcom,mdss-dsc-version = <0x11>;
						qcom,mdss-dsi-cmd-mode;
						qcom,mdss-dsi-h-back-porch = <0x10>;
						qcom,mdss-dsi-h-front-porch = <0x10>;
						qcom,mdss-dsi-h-left-border = <0x0>;
						qcom,mdss-dsi-h-pulse-width = <0x20>;
						qcom,mdss-dsi-h-right-border = <0x0>;
						qcom,mdss-dsi-h-sync-pulse = <0x0>;
						qcom,mdss-dsi-h-sync-skew = <0x0>;
						qcom,mdss-dsi-nolp-command = <0x39000000 0x6f0 0x55aa5208 0x390000 0x40000002 0xb2183900 0x0 0x2380039 0x0 0x22f02>;
						qcom,mdss-dsi-nolp-command-state = "dsi_hs_mode";
						qcom,mdss-dsi-off-command = [39 00 00 00 14 00 02 28 00 39 00 00 00 78 00 02 10 00];
						qcom,mdss-dsi-off-command-state = "dsi_lp_mode";
						qcom,mdss-dsi-on-command = [39 00 00 00 00 00 06 f0 55 aa 52 08 00 39 00 00 40 00 00 02 6f 08 39 00 00 40 00 00 09 ba 01 b1 00 0a 00 16 00 00 39 00 00 40 00 00 06 f0 55 aa 52 08 04 39 00 00 40 00 00 02 b1 02 39 00 00 40 00 00 05 3b 00 14 00 0c 39 00 00 40 00 00 02 90 01 39 00 00 40 00 00 13 91 ab 28 00 0c c2 00 03 1c 01 7e 00 0f 08 bb 04 3d 10 f0 39 00 00 40 00 00 02 03 01 39 00 00 40 00 00 02 2c 00 39 00 00 40 00 00 06 f0 55 aa 52 08 07 39 00 00 40 00 00 02 c0 05 39 00 00 40 00 00 02 c1 00 39 00 00 40 00 00 02 c2 00 39 00 00 40 00 00 02 c3 00 39 00 00 40 00 00 02 c4 00 39 00 00 40 00 00 02 c5 00 39 00 00 40 00 00 02 c6 00 39 00 00 40 00 00 02 c7 00 39 00 00 40 00 00 02 c8 00 39 00 00 40 00 00 02 cd 00 39 00 00 40 00 00 02 ce 00 39 00 00 40 00 00 02 cf 00 39 00 00 40 00 00 02 d0 00 39 00 00 40 00 00 02 53 20 39 00 00 40 00 00 06 f0 55 aa 52 08 00 39 00 00 40 00 00 02 6f 02 39 00 00 40 00 00 03 b2 08 08 39 00 00 40 00 00 02 35 00 39 00 00 40 00 00 06 f0 55 aa 52 08 01 39 00 00 40 00 00 08 c3 94 01 8c d0 22 02 00 39 00 00 40 00 00 05 2a 00 00 04 37 39 00 00 40 00 00 05 2b 00 00 09 5f 39 00 00 40 00 00 02 2f 02 39 00 00 40 00 00 06 f0 55 aa 52 08 00 39 00 00 40 00 00 02 6f 09 39 00 00 40 00 00 02 c0 20 39 00 00 40 00 00 06 f0 55 aa 52 08 02 39 00 00 40 00 00 02 cc 30 39 00 00 40 14 00 02 ce 01 39 00 00 40 00 00 02 cc 00 39 00 00 40 00 00 06 f0 55 aa 52 08 00 39 00 00 40 00 00 02 6f 05 39 00 00 00 00 00 02 be 88 39 00 00 40 00 00 05 ff aa 55 a5 80 39 00 00 40 00 00 02 6f 61 39 00 00 40 00 00 02 f3 80 39 00 00 40 00 00 06 f0 55 aa 52 08 01 39 00 00 40 00 00 02 6f 01 39 00 00 40 00 00 04 d2 00 00 11 39 00 00 40 00 00 02 6f 06 39 00 00 40 00 00 02 d2 05 39 00 00 40 00 00 02 6f 0f 39 00 00 40 00 00 02 d2 00 39 00 00 40 00 00 02 6f 09 39 00 00 00 00 00 03 d2 00 00 39 00 00 40 00 00 06 f0 55 aa 52 08 00 39 00 00 40 00 00 02 6f 01 39 00 00 40 00 00 02 c0 b3 39 00 00 40 00 00 05 ff aa 55 a5 80 39 00 00 40 00 00 02 6f 2e 39 00 00 40 00 00 02 fb d1 39 00 00 40 00 00 06 f0 55 aa 52 08 04 39 00 00 40 00 00 02 6f 0d 39 00 00 00 00 00 02 ca 05 39 00 00 40 00 00 06 f0 55 aa 52 08 07 39 00 00 40 00 00 02 c0 05 39 00 00 40 00 00 02 6f 00 39 00 00 40 00 00 16 c9 21 00 21 c9 21 10 00 00 3f e7 b7 88 3f e7 fa 60 80 04 5d 05 90 39 00 00 40 00 00 02 6f 15 39 00 00 40 00 00 10 c9 81 c0 16 82 1c 73 33 a0 21 6c 0f a3 a4 00 00 39 00 00 40 00 00 02 6f 24 39 00 00 40 00 00 08 c9 00 00 00 00 00 00 00 39 00 00 40 00 00 02 6f 00 39 00 00 40 00 00 16 ca 27 00 21 c9 21 10 00 00 00 00 00 00 3f e7 fa 60 80 00 00 00 00 39 00 00 40 00 00 02 6f 15 39 00 00 40 00 00 10 ca 82 1d 16 82 79 73 33 a0 00 00 03 5d a4 00 00 39 00 00 40 00 00 02 6f 24 39 00 00 40 00 00 08 ca 00 00 00 00 00 00 00 39 00 00 40 00 00 02 6f 00 39 00 00 40 00 00 16 cb 2d 00 21 10 21 10 00 00 3f e8 3c 80 80 00 00 00 00 00 00 00 00 39 00 00 40 00 00 02 6f 15 39 00 00 40 00 00 10 cb 81 c0 74 82 1c d0 33 10 00 00 0c a4 5c 00 00 39 00 00 40 00 00 02 6f 24 39 00 00 40 00 00 08 cb 00 00 00 00 00 00 00 39 00 00 40 00 00 02 6f 00 39 00 00 40 00 00 16 cc 2b 00 21 10 21 10 00 00 00 00 00 00 80 00 00 00 7f fb ba df 00 39 00 00 40 00 00 02 6f 15 39 00 00 40 00 00 10 cc 82 1d 74 82 79 d0 33 1f de f0 00 5c 5c 00 00 39 00 00 40 00 00 02 6f 24 39 00 00 00 00 00 08 cc 00 00 00 00 00 00 00 39 00 00 40 00 00 06 f0 55 aa 52 08 01 39 00 00 00 00 00 07 b7 20 20 20 20 20 20 39 00 00 00 50 00 02 11 00 39 00 00 00 00 00 02 29 00];
						qcom,mdss-dsi-on-command-state = "dsi_lp_mode";
						qcom,mdss-dsi-panel-clockrate = <0x31880dc0>;
						qcom,mdss-dsi-panel-framerate = <0x78>;
						qcom,mdss-dsi-panel-height = <0x960>;
						qcom,mdss-dsi-panel-jitter = <0x5 0x1>;
						qcom,mdss-dsi-panel-phy-timings = [00 1d 07 07 17 22 07 07 08 02 04 00 19 0c];
						qcom,mdss-dsi-panel-width = <0x438>;
						qcom,mdss-dsi-timing-switch-command = [39 00 00 00 00 00 02 2f 02 39 00 00 40 00 00 06 f0 55 aa 52 08 00 39 00 00 40 00 00 02 6f 09 39 00 00 40 00 00 02 c0 20 39 00 00 40 00 00 06 f0 55 aa 52 08 02 39 00 00 40 00 00 02 cc 30 39 00 00 00 14 00 02 ce 01 39 00 00 00 00 00 06 f0 55 aa 52 08 02 39 00 00 00 00 00 02 cc 00];
						qcom,mdss-dsi-timing-switch-command-state = "dsi_hs_mode";
						qcom,mdss-dsi-timing-switch-command-update = <0xc0 0x3 0x1>;
						qcom,mdss-dsi-v-back-porch = <0x40>;
						qcom,mdss-dsi-v-bottom-border = <0x0>;
						qcom,mdss-dsi-v-front-porch = <0x60>;
						qcom,mdss-dsi-v-pulse-width = <0x40>;
						qcom,mdss-dsi-v-top-border = <0x0>;
						qcom,mdss-mdp-transfer-time-us = <0x1f40>;
					};

					timing@2 {
						mi,mdss-dsc-panel-id = <0x4c3953 0x420200>;
						mi,mdss-dsi-dimmingoff-command = [39 00 00 00 00 00 02 53 20];
						mi,mdss-dsi-dimmingoff-command-state = "dsi_hs_mode";
						mi,mdss-dsi-dimmingon-command = [39 00 00 00 00 00 02 53 28];
						mi,mdss-dsi-dimmingon-command-state = "dsi_hs_mode";
						mi,mdss-dsi-doze-hbm-command = [39 00 00 00 00 00 02 2f 01 39 00 00 40 00 00 02 26 01 39 00 00 40 00 00 06 f0 55 aa 52 08 00 39 00 00 40 00 00 02 b2 08 39 00 00 40 00 00 05 51 00 f5 0f fe 39 00 00 00 00 00 02 39 00];
						mi,mdss-dsi-doze-hbm-command-state = "dsi_lp_mode";
						mi,mdss-dsi-doze-hbm-nolp-command = [39 00 00 00 00 00 06 f0 55 aa 52 08 00 39 00 00 40 00 00 02 b2 18 39 00 00 40 00 00 05 51 00 f5 0f fe 39 00 00 00 00 00 02 38 00];
						mi,mdss-dsi-doze-hbm-nolp-command-state = "dsi_lp_mode";
						mi,mdss-dsi-doze-lbm-command = [39 00 00 00 00 00 02 2f 01 39 00 00 40 00 00 02 26 01 39 00 00 40 00 00 06 f0 55 aa 52 08 00 39 00 00 40 00 00 02 b2 08 39 00 00 40 00 00 05 51 00 14 01 55 39 00 00 00 00 00 02 39 00];
						mi,mdss-dsi-doze-lbm-command-state = "dsi_lp_mode";
						mi,mdss-dsi-doze-lbm-nolp-command = [39 00 00 00 00 00 06 f0 55 aa 52 08 00 39 00 00 40 00 00 02 b2 18 39 00 00 40 00 00 05 51 00 14 01 55 39 00 00 00 00 00 02 38 00];
						mi,mdss-dsi-doze-lbm-nolp-command-state = "dsi_lp_mode";
						mi,mdss-dsi-flat-mode-off-command = [39 00 00 00 00 00 02 2f 03 39 00 00 40 00 00 06 f0 55 aa 52 08 00 39 00 00 40 00 00 02 6f 0a 39 00 00 40 00 00 02 c0 20 39 00 00 40 00 00 06 f0 55 aa 52 08 02 39 00 00 40 00 00 02 cc 30 39 00 00 40 00 00 02 ce 01 39 00 00 40 00 00 06 f0 55 aa 52 08 08 39 00 00 40 00 00 02 6f 07 39 00 00 20 14 00 05 b9 00 00 00 18];
						mi,mdss-dsi-flat-mode-off-command-state = "dsi_lp_mode";
						mi,mdss-dsi-flat-mode-off-command-update = <0xb9 0x9 0x4>;
						mi,mdss-dsi-flat-mode-off-read-pre-command = [39 00 00 00 00 00 06 f0 55 aa 52 08 00 39 00 00 00 00 00 02 6f 48];
						mi,mdss-dsi-flat-mode-off-read-pre-command-state = "dsi_lp_mode";
						mi,mdss-dsi-flat-mode-off-sec-command = [39 00 00 00 00 00 06 f0 55 aa 52 08 02 39 00 00 00 00 00 02 cc 00];
						mi,mdss-dsi-flat-mode-off-sec-command-state = "dsi_lp_mode";
						mi,mdss-dsi-flat-mode-on-command = [39 00 00 00 00 00 02 2f 03 39 00 00 40 00 00 06 f0 55 aa 52 08 00 39 00 00 40 00 00 02 6f 0a 39 00 00 40 00 00 02 c0 60 39 00 00 40 00 00 06 f0 55 aa 52 08 02 39 00 00 40 00 00 02 cc 30 39 00 00 40 00 00 02 ce 01 39 00 00 40 00 00 06 f0 55 aa 52 08 08 39 00 00 40 00 00 02 6f 07 39 00 00 20 14 00 05 b9 00 00 00 00];
						mi,mdss-dsi-flat-mode-on-command-state = "dsi_lp_mode";
						mi,mdss-dsi-flat-mode-on-command-update = <0xb9 0x9 0x4>;
						mi,mdss-dsi-flat-mode-on-sec-command = [39 00 00 00 00 00 06 f0 55 aa 52 08 02 39 00 00 00 00 00 02 cc 00];
						mi,mdss-dsi-flat-mode-on-sec-command-state = "dsi_lp_mode";
						mi,mdss-dsi-flat-mode-read-pre-command = [39 00 00 00 00 00 06 f0 55 aa 52 08 00 39 00 00 00 00 00 02 6f 3f];
						mi,mdss-dsi-flat-mode-read-pre-command-state = "dsi_lp_mode";
						mi,mdss-dsi-hbm-off-command = <0x39000000 0x551 0x7ff0000>;
						mi,mdss-dsi-hbm-off-command-state = "dsi_lp_mode";
						mi,mdss-dsi-hbm-on-command = <0x39000000 0x551 0xfff0000>;
						mi,mdss-dsi-hbm-on-command-state = "dsi_lp_mode";
						mi,mdss-dsi-local-hbm-hlpm-white-1000nit-command = [39 00 00 00 00 00 06 f0 55 aa 52 08 00 39 00 00 40 00 00 02 b2 18 39 00 00 40 00 00 02 38 00 39 00 00 40 00 00 06 f0 55 aa 52 08 00 39 00 00 40 00 00 02 6f 29 39 00 00 40 00 00 02 d9 00 39 00 00 40 00 00 02 6f 01 39 00 00 40 00 00 02 d9 80 39 00 00 40 00 00 02 6f 07 39 00 00 40 00 00 03 b2 07 ff 39 00 00 40 00 00 02 6f 17 39 00 00 40 00 00 03 b2 07 ff 39 00 00 40 00 00 02 6f 1f 39 00 00 40 00 00 03 b2 00 50 39 00 00 40 00 00 06 f0 55 aa 52 08 02 39 00 00 40 00 00 02 6f 08 39 00 00 40 00 00 07 d0 0b 07 09 7b 0c 1d 39 00 00 40 00 00 06 f0 55 aa 52 08 07 39 00 00 40 00 00 02 c0 05 39 00 00 40 00 00 02 53 20 39 00 00 40 00 00 05 88 02 1c 08 73 39 00 00 40 00 00 03 51 07 ff 39 00 00 40 00 00 03 87 04 4e 39 00 00 40 00 00 02 6f 02 39 00 00 00 30 00 02 87 05];
						mi,mdss-dsi-local-hbm-hlpm-white-1000nit-command-state = "dsi_hs_mode";
						mi,mdss-dsi-local-hbm-hlpm-white-1000nit-command-update = <0x87 0x16 0x2 0xd0 0x10 0x6>;
						mi,mdss-dsi-local-hbm-hlpm-white-110nit-command = [39 00 00 00 00 00 06 f0 55 aa 52 08 00 39 00 00 40 00 00 02 b2 18 39 00 00 40 00 00 02 38 00 39 00 00 40 00 00 06 f0 55 aa 52 08 00 39 00 00 40 00 00 02 6f 29 39 00 00 40 00 00 02 d9 00 39 00 00 40 00 00 02 6f 01 39 00 00 40 00 00 02 d9 80 39 00 00 40 00 00 02 6f 07 39 00 00 40 00 00 03 b2 07 ff 39 00 00 40 00 00 02 6f 17 39 00 00 40 00 00 03 b2 07 ff 39 00 00 40 00 00 02 6f 1f 39 00 00 40 00 00 03 b2 00 50 39 00 00 40 00 00 06 f0 55 aa 52 08 02 39 00 00 40 00 00 02 6f 08 39 00 00 40 00 00 07 d0 0b 07 09 7b 0c 1d 39 00 00 40 00 00 06 f0 55 aa 52 08 07 39 00 00 40 00 00 02 c0 05 39 00 00 40 00 00 02 53 20 39 00 00 40 00 00 05 88 02 1c 08 73 39 00 00 40 00 00 03 51 07 ff 39 00 00 40 00 00 03 87 04 4e 39 00 00 40 00 00 02 6f 02 39 00 00 00 30 00 02 87 05];
						mi,mdss-dsi-local-hbm-hlpm-white-110nit-command-state = "dsi_hs_mode";
						mi,mdss-dsi-local-hbm-hlpm-white-110nit-command-update = <0x87 0x16 0x2 0xd0 0x10 0x6>;
						mi,mdss-dsi-local-hbm-normal-green-500nit-command = [39 00 00 00 00 00 06 f0 55 aa 52 08 00 39 00 00 40 00 00 02 6f 29 39 00 00 40 00 00 02 d9 00 39 00 00 40 00 00 02 6f 01 39 00 00 40 00 00 02 d9 80 39 00 00 40 00 00 02 6f 07 39 00 00 40 00 00 03 b2 07 ff 39 00 00 40 00 00 02 6f 17 39 00 00 40 00 00 03 b2 07 ff 39 00 00 40 00 00 02 6f 1f 39 00 00 40 00 00 03 b2 00 50 39 00 00 40 00 00 06 f0 55 aa 52 08 02 39 00 00 40 00 00 02 6f 08 39 00 00 40 00 00 07 d0 00 00 09 40 00 00 39 00 00 40 00 00 06 f0 55 aa 52 08 07 39 00 00 40 00 00 02 c0 05 39 00 00 40 00 00 02 53 20 39 00 00 40 00 00 05 88 02 1c 08 73 39 00 00 40 00 00 03 51 07 ff 39 00 00 40 00 00 03 87 04 4e 39 00 00 40 00 00 02 6f 02 39 00 00 00 30 00 02 87 05];
						mi,mdss-dsi-local-hbm-normal-green-500nit-command-state = "dsi_hs_mode";
						mi,mdss-dsi-local-hbm-normal-green-500nit-command-update = <0x87 0x13 0x2 0xd0 0xd 0x6>;
						mi,mdss-dsi-local-hbm-normal-white-1000nit-command = [39 00 00 00 00 00 06 f0 55 aa 52 08 00 39 00 00 40 00 00 02 6f 29 39 00 00 40 00 00 02 d9 00 39 00 00 40 00 00 02 6f 01 39 00 00 40 00 00 02 d9 80 39 00 00 40 00 00 02 6f 07 39 00 00 40 00 00 03 b2 07 ff 39 00 00 40 00 00 02 6f 17 39 00 00 40 00 00 03 b2 07 ff 39 00 00 40 00 00 02 6f 1f 39 00 00 40 00 00 03 b2 00 50 39 00 00 40 00 00 06 f0 55 aa 52 08 02 39 00 00 40 00 00 02 6f 08 39 00 00 40 00 00 07 d0 0b 07 09 7b 0c 1d 39 00 00 40 00 00 06 f0 55 aa 52 08 07 39 00 00 40 00 00 02 c0 05 39 00 00 40 00 00 02 53 20 39 00 00 40 00 00 05 88 02 1c 08 73 39 00 00 40 00 00 03 51 07 ff 39 00 00 40 00 00 03 87 04 4e 39 00 00 40 00 00 02 6f 02 39 00 00 00 30 00 02 87 05];
						mi,mdss-dsi-local-hbm-normal-white-1000nit-command-state = "dsi_hs_mode";
						mi,mdss-dsi-local-hbm-normal-white-1000nit-command-update = <0x87 0x13 0x2 0xd0 0xd 0x6>;
						mi,mdss-dsi-local-hbm-normal-white-110nit-command = [39 00 00 00 00 00 06 f0 55 aa 52 08 00 39 00 00 40 00 00 02 6f 29 39 00 00 40 00 00 02 d9 00 39 00 00 40 00 00 02 6f 01 39 00 00 40 00 00 02 d9 80 39 00 00 40 00 00 02 6f 07 39 00 00 40 00 00 03 b2 07 ff 39 00 00 40 00 00 02 6f 17 39 00 00 40 00 00 03 b2 07 ff 39 00 00 40 00 00 02 6f 1f 39 00 00 40 00 00 03 b2 00 50 39 00 00 40 00 00 06 f0 55 aa 52 08 02 39 00 00 40 00 00 02 6f 08 39 00 00 40 00 00 07 d0 0b 07 09 7b 0c 1d 39 00 00 40 00 00 06 f0 55 aa 52 08 07 39 00 00 40 00 00 02 c0 05 39 00 00 40 00 00 02 53 20 39 00 00 40 00 00 05 88 02 1c 08 73 39 00 00 40 00 00 03 51 07 ff 39 00 00 40 00 00 03 87 04 4e 39 00 00 40 00 00 02 6f 02 39 00 00 00 30 00 02 87 05];
						mi,mdss-dsi-local-hbm-normal-white-110nit-command-state = "dsi_hs_mode";
						mi,mdss-dsi-local-hbm-normal-white-110nit-command-update = <0x87 0x13 0x2 0xd0 0xd 0x6>;
						mi,mdss-dsi-local-hbm-off-to-hbm-command = [39 00 00 00 00 00 02 53 20 39 00 00 40 00 00 03 51 00 00 39 00 00 40 00 00 02 6f 02 39 00 00 00 00 00 02 87 04];
						mi,mdss-dsi-local-hbm-off-to-hbm-command-state = "dsi_hs_mode";
						mi,mdss-dsi-local-hbm-off-to-hbm-command-update = <0x51 0x1 0x2>;
						mi,mdss-dsi-local-hbm-off-to-hlpm-command = [39 00 00 00 00 00 02 53 20 39 00 00 40 00 00 03 51 00 00 39 00 00 40 00 00 02 6f 02 39 00 00 40 00 00 02 87 04 39 00 00 40 00 00 02 2f 01 39 00 00 40 00 00 02 26 01 39 00 00 40 00 00 06 f0 55 aa 52 08 00 39 00 00 40 00 00 02 b2 08 39 00 00 40 00 00 05 51 00 f5 0f ff 39 00 00 00 00 00 02 39 00];
						mi,mdss-dsi-local-hbm-off-to-hlpm-command-state = "dsi_hs_mode";
						mi,mdss-dsi-local-hbm-off-to-llpm-command = [39 00 00 00 00 00 02 53 20 39 00 00 40 00 00 03 51 00 00 39 00 00 40 00 00 02 6f 02 39 00 00 40 00 00 02 87 04 39 00 00 40 00 00 02 2f 01 39 00 00 40 00 00 02 26 01 39 00 00 40 00 00 06 f0 55 aa 52 08 00 39 00 00 40 00 00 02 b2 08 39 00 00 40 00 00 05 51 00 14 01 55 39 00 00 00 00 00 02 39 00];
						mi,mdss-dsi-local-hbm-off-to-llpm-command-state = "dsi_hs_mode";
						mi,mdss-dsi-local-hbm-off-to-normal-command = [39 00 00 00 00 00 02 53 20 39 00 00 40 00 00 03 51 00 00 39 00 00 40 00 00 02 6f 02 39 00 00 00 00 00 02 87 04];
						mi,mdss-dsi-local-hbm-off-to-normal-command-state = "dsi_hs_mode";
						mi,mdss-dsi-local-hbm-off-to-normal-command-update = <0x51 0x1 0x2>;
						mi,mdss-dsi-pre-doze-to-off-command = [39 01 00 00 00 00 06 f0 55 aa 52 08 01 39 01 00 00 00 00 02 ce 0c];
						mi,mdss-dsi-pre-doze-to-off-command-state = "dsi_hs_mode";
						mi,mdss-dsi-switch-page-command = [39 00 00 00 00 00 06 f0 55 aa 52 08 00];
						mi,mdss-dsi-switch-page-command-state = "dsi_lp_mode";
						mi,mdss-dsi-switch-page-command-update = <0xf0 0x0 0x5>;
						mi,mdss-flat-status-control-gamma-cfg = <0x60 0x20>;
						qcom,compression-mode = "dsc";
						qcom,default-topology-index = <0x0>;
						qcom,display-topology = <0x1 0x1 0x1>;
						qcom,mdss-dsc-bit-per-component = <0xa>;
						qcom,mdss-dsc-bit-per-pixel = <0x8>;
						qcom,mdss-dsc-block-prediction-enable;
						qcom,mdss-dsc-scr-version = <0x0>;
						qcom,mdss-dsc-slice-height = <0xc>;
						qcom,mdss-dsc-slice-per-pkt = <0x1>;
						qcom,mdss-dsc-slice-width = <0x438>;
						qcom,mdss-dsc-version = <0x11>;
						qcom,mdss-dsi-cmd-mode;
						qcom,mdss-dsi-h-back-porch = <0x20>;
						qcom,mdss-dsi-h-front-porch = <0x40>;
						qcom,mdss-dsi-h-left-border = <0x0>;
						qcom,mdss-dsi-h-pulse-width = <0x20>;
						qcom,mdss-dsi-h-right-border = <0x0>;
						qcom,mdss-dsi-h-sync-pulse = <0x0>;
						qcom,mdss-dsi-h-sync-skew = <0x0>;
						qcom,mdss-dsi-nolp-command = <0x39000000 0x6f0 0x55aa5208 0x390000 0x40000002 0xb2183900 0x0 0x2380039 0x0 0x22f03>;
						qcom,mdss-dsi-nolp-command-state = "dsi_hs_mode";
						qcom,mdss-dsi-off-command = [39 00 00 00 14 00 02 28 00 39 00 00 00 78 00 02 10 00];
						qcom,mdss-dsi-off-command-state = "dsi_lp_mode";
						qcom,mdss-dsi-on-command = [39 00 00 40 00 00 06 f0 55 aa 52 08 00 39 00 00 40 00 00 02 6f 08 39 00 00 40 00 00 09 ba 01 b1 00 0a 00 16 00 00 39 00 00 40 00 00 06 f0 55 aa 52 08 04 39 00 00 40 00 00 02 b1 02 39 00 00 40 00 00 05 3b 00 14 00 0c 39 00 00 40 00 00 02 90 01 39 00 00 40 00 00 13 91 ab 28 00 0c c2 00 03 1c 01 7e 00 0f 08 bb 04 3d 10 f0 39 00 00 40 00 00 02 03 01 39 00 00 40 00 00 02 2c 00 39 00 00 40 00 00 06 f0 55 aa 52 08 07 39 00 00 40 00 00 02 c0 05 39 00 00 40 00 00 02 c1 00 39 00 00 40 00 00 02 c2 00 39 00 00 40 00 00 02 c3 00 39 00 00 40 00 00 02 c4 00 39 00 00 40 00 00 02 c5 00 39 00 00 40 00 00 02 c6 00 39 00 00 40 00 00 02 c7 00 39 00 00 40 00 00 02 c8 00 39 00 00 40 00 00 02 cd 00 39 00 00 40 00 00 02 ce 00 39 00 00 40 00 00 02 cf 00 39 00 00 40 00 00 02 d0 00 39 00 00 40 00 00 02 53 20 39 00 00 40 00 00 06 f0 55 aa 52 08 00 39 00 00 40 00 00 02 6f 02 39 00 00 40 00 00 03 b2 08 08 39 00 00 40 00 00 02 35 00 39 00 00 40 00 00 06 f0 55 aa 52 08 01 39 00 00 40 00 00 08 c3 94 01 8c d0 22 02 00 39 00 00 40 00 00 05 2a 00 00 04 37 39 00 00 40 00 00 05 2b 00 00 09 5f 39 00 00 40 00 00 02 2f 03 39 00 00 40 00 00 06 f0 55 aa 52 08 00 39 00 00 40 00 00 02 6f 0a 39 00 00 40 00 00 02 c0 20 39 00 00 40 00 00 06 f0 55 aa 52 08 02 39 00 00 40 00 00 02 cc 30 39 00 00 40 14 00 02 ce 01 39 00 00 40 00 00 02 cc 00 39 00 00 40 00 00 06 f0 55 aa 52 08 00 39 00 00 40 00 00 02 6f 05 39 00 00 00 00 00 02 be 88 39 00 00 40 00 00 05 ff aa 55 a5 80 39 00 00 40 00 00 02 6f 61 39 00 00 40 00 00 02 f3 80 39 00 00 40 00 00 06 f0 55 aa 52 08 01 39 00 00 40 00 00 02 6f 01 39 00 00 40 00 00 04 d2 00 00 11 39 00 00 40 00 00 02 6f 06 39 00 00 40 00 00 02 d2 05 39 00 00 40 00 00 02 6f 0f 39 00 00 40 00 00 02 d2 00 39 00 00 40 00 00 02 6f 09 39 00 00 00 00 00 03 d2 00 00 39 00 00 40 00 00 06 f0 55 aa 52 08 00 39 00 00 40 00 00 02 6f 01 39 00 00 40 00 00 02 c0 b3 39 00 00 40 00 00 05 ff aa 55 a5 80 39 00 00 40 00 00 02 6f 2e 39 00 00 40 00 00 02 fb d1 39 00 00 40 00 00 06 f0 55 aa 52 08 04 39 00 00 40 00 00 02 6f 0d 39 00 00 00 00 00 02 ca 05 39 00 00 40 00 00 06 f0 55 aa 52 08 07 39 00 00 40 00 00 02 c0 05 39 00 00 40 00 00 02 6f 00 39 00 00 40 00 00 16 c9 21 00 21 c9 21 10 00 00 3f e7 b7 88 3f e7 fa 60 80 04 5d 05 90 39 00 00 40 00 00 02 6f 15 39 00 00 40 00 00 10 c9 81 c0 16 82 1c 73 33 a0 21 6c 0f a3 a4 00 00 39 00 00 40 00 00 02 6f 24 39 00 00 40 00 00 08 c9 00 00 00 00 00 00 00 39 00 00 40 00 00 02 6f 00 39 00 00 40 00 00 16 ca 27 00 21 c9 21 10 00 00 00 00 00 00 3f e7 fa 60 80 00 00 00 00 39 00 00 40 00 00 02 6f 15 39 00 00 40 00 00 10 ca 82 1d 16 82 79 73 33 a0 00 00 03 5d a4 00 00 39 00 00 40 00 00 02 6f 24 39 00 00 40 00 00 08 ca 00 00 00 00 00 00 00 39 00 00 40 00 00 02 6f 00 39 00 00 40 00 00 16 cb 2d 00 21 10 21 10 00 00 3f e8 3c 80 80 00 00 00 00 00 00 00 00 39 00 00 40 00 00 02 6f 15 39 00 00 40 00 00 10 cb 81 c0 74 82 1c d0 33 10 00 00 0c a4 5c 00 00 39 00 00 40 00 00 02 6f 24 39 00 00 40 00 00 08 cb 00 00 00 00 00 00 00 39 00 00 40 00 00 02 6f 00 39 00 00 40 00 00 16 cc 2b 00 21 10 21 10 00 00 00 00 00 00 80 00 00 00 7f fb ba df 00 39 00 00 40 00 00 02 6f 15 39 00 00 40 00 00 10 cc 82 1d 74 82 79 d0 33 1f de f0 00 5c 5c 00 00 39 00 00 40 00 00 02 6f 24 39 00 00 00 00 00 08 cc 00 00 00 00 00 00 00 39 00 00 40 00 00 06 f0 55 aa 52 08 01 39 00 00 00 00 00 07 b7 20 20 20 20 20 20 39 00 00 00 50 00 02 11 00 39 00 00 00 00 00 02 29 00];
						qcom,mdss-dsi-on-command-state = "dsi_lp_mode";
						qcom,mdss-dsi-panel-clockrate = <0x31880dc0>;
						qcom,mdss-dsi-panel-framerate = <0x5a>;
						qcom,mdss-dsi-panel-height = <0x960>;
						qcom,mdss-dsi-panel-jitter = <0x5 0x1>;
						qcom,mdss-dsi-panel-phy-timings = [00 1d 07 07 17 22 07 07 08 02 04 00 19 0c];
						qcom,mdss-dsi-panel-width = <0x438>;
						qcom,mdss-dsi-timing-switch-command = [39 00 00 00 00 00 02 2f 03 39 00 00 40 00 00 06 f0 55 aa 52 08 00 39 00 00 40 00 00 02 6f 0a 39 00 00 40 00 00 02 c0 20 39 00 00 40 00 00 06 f0 55 aa 52 08 02 39 00 00 40 00 00 02 cc 30 39 00 00 00 14 00 02 ce 01 39 00 00 00 00 00 06 f0 55 aa 52 08 02 39 00 00 00 00 00 02 cc 00];
						qcom,mdss-dsi-timing-switch-command-state = "dsi_hs_mode";
						qcom,mdss-dsi-timing-switch-command-update = <0xc0 0x3 0x1>;
						qcom,mdss-dsi-v-back-porch = <0x82>;
						qcom,mdss-dsi-v-bottom-border = <0x0>;
						qcom,mdss-dsi-v-front-porch = <0x12c>;
						qcom,mdss-dsi-v-pulse-width = <0x82>;
						qcom,mdss-dsi-v-top-border = <0x0>;
						qcom,mdss-mdp-transfer-time-us = <0x2710>;
					};
				};
			};
};

&dsi_l9s_42_02_0a_mp_amoled_dsc_cmd {
	mi,panel-id = <0x004C3953 0x00420200>;
	mi,hbm-51-ctl-flag;
	mi,bl-51ctl-32bit-flag;
	mi,aod-bl-51ctl-flag;
	mi,aod-brightness = <0x155 0x0FFE>;
	mi,hbm-off-51-index = <0>;
	mi,hbm-fod-off-51-index = <0>;
	mi,hbm-bl-min-level = <1>;
	mi,hbm-bl-max-level = <2047>;
	mi,max-brightness-clone = <4095>;
	mi,mdss-dsi-fac-bl-max-level = <2047>;
	mi,mdss-fac-brightness-max-level = <2047>;
	mi,thermal-dimming-flag;
	mi,mdss-dsi-panel-dc-type = <0>;

	mi,local-hbm-enabled;
	mi,doze-hbm-dbv-level = <245>;
	mi,doze-lbm-dbv-level = <20>;
	mi,fod-low-brightness-clone-threshold = <38>;
	mi,fod-low-brightness-lux-threshold = <1>;
	mi,local-hbm-white-1000nit-update-flag;
	mi,local-hbm-white-110nit-update-flag;
	mi,local-hbm-green-500nit-update-flag;
	mi,local-hbm-alpha-ctrl-aa-area;
	mi,need-fod-animal-in-normal-enabled;

	mi,flat-update-flag;
	mi,flat-need-sync-te;

	/* IRQF_ONESHOT | IRQF_TRIGGER_LOW */
	mi,esd-err-irq-gpio = <&tlmm 11 0x2008>;

	mi,panel-aod-to-off-command-need-enabled;

	mi,panel-on-dimming-delay = <120>;

	qcom,esd-check-enabled;
	qcom,esd-aod-check-enabled;
	qcom,mdss-dsi-panel-status-check-mode = "reg_read";
	qcom,mdss-dsi-panel-status-offset-command = [
		39 01 00 00 00 00 05 FF AA 55 A5 81
		15 01 00 00 00 00 02 6F 0F];
	qcom,mdss-dsi-panel-status-command = [06 01 00 00 00 00 01 FA];
	qcom,mdss-dsi-panel-status-command-state = "dsi_lp_mode";
	qcom,mdss-dsi-panel-status-offset-command-state = "dsi_lp_mode";
	qcom,mdss-dsi-panel-status-value = <0x00>;
	qcom,mdss-dsi-panel-status-read-length = <1>;

	qcom,mdss-dsi-display-timings {
		/* 60Hz */
		timing@0{
			mi,mdss-dsc-panel-id = <0x004C3953 0x00420200>;
			/*<flat on gamma, flat off gamma>*/
			mi,mdss-flat-status-control-gamma-cfg = <0x04 0x01>;
			mi,mdss-dsi-dimmingon-command = [39 00 00 00 00 00 02 53 28];
			mi,mdss-dsi-dimmingon-command-state = "dsi_hs_mode";
			mi,mdss-dsi-dimmingoff-command = [39 00 00 00 00 00 02 53 20];
			mi,mdss-dsi-dimmingoff-command-state = "dsi_hs_mode";

			mi,mdss-dsi-hbm-on-command = [39 00 00 00 00 00 05 51 0F FF 00 00];
			mi,mdss-dsi-hbm-on-command-state = "dsi_lp_mode";
			mi,mdss-dsi-hbm-off-command = [39 00 00 00 00 00 05 51 07 FF 00 00];
			mi,mdss-dsi-hbm-off-command-state = "dsi_lp_mode";
			mi,mdss-dsi-switch-page-command = [
			/* switch page, last byte is page config */
				39 00 00 00 00 00 06 F0 55 AA 52 08 00
			];
			/* <mipi_address  update_index  update_length> */
			mi,mdss-dsi-switch-page-command-update = <0xF0 0 5>;
			mi,mdss-dsi-switch-page-command-state = "dsi_lp_mode";

			mi,mdss-dsi-flat-mode-read-pre-command = [
				39 00 00 00 00 00 06 F0 55 AA 52 08 00
				39 00 00 00 00 00 02 6F 3F
			];
			mi,mdss-dsi-flat-mode-read-pre-command-state = "dsi_lp_mode";

			mi,mdss-dsi-flat-mode-off-read-pre-command = [
				39 00 00 00 00 00 06 F0 55 AA 52 08 00
				39 00 00 00 00 00 02 6F 48
			];
			mi,mdss-dsi-flat-mode-off-read-pre-command-state = "dsi_lp_mode";

			mi,mdss-dsi-flat-mode-on-command = [
				/* 60 Hz */
				39 00 00 00 00 00 02 2F 01
				39 00 00 40 00 00 02 26 04
				39 00 00 40 00 00 06 F0 55 AA 52 08 08
				39 00 00 40 00 00 02 6F 07
				39 00 00 20 00 00 05 B9 00 00 00 00
			];
			/* <mipi_address  update_index  update_length> */
			mi,mdss-dsi-flat-mode-on-command-update = <0xB9 4 4>;
			mi,mdss-dsi-flat-mode-on-command-state = "dsi_lp_mode";

			mi,mdss-dsi-flat-mode-off-command = [
				/* 60 Hz */
				39 00 00 00 00 00 02 2F 01
				39 00 00 40 00 00 02 26 01
				39 00 00 40 00 00 06 F0 55 AA 52 08 08
				39 00 00 40 00 00 02 6F 07
				39 00 00 20 00 00 05 B9 00 00 00 18
			];
			/* <mipi_address  update_index  update_length> */
			mi,mdss-dsi-flat-mode-off-command-update = <0xB9 4 4>;
			mi,mdss-dsi-flat-mode-off-command-state = "dsi_lp_mode";

			mi,mdss-dsi-doze-hbm-command = [
				39 00 00 00 00 00 02 2F 01
				39 00 00 40 00 00 02 26 01
				39 00 00 40 00 00 06 F0 55 AA 52 08 00
				39 00 00 40 00 00 02 B2 08
				39 00 00 40 00 00 05 51 00 F5 0F FE
				39 00 00 00 00 00 02 39 00
			];
			mi,mdss-dsi-doze-hbm-command-state = "dsi_lp_mode";

			mi,mdss-dsi-doze-lbm-command = [
				39 00 00 00 00 00 02 2F 01
				39 00 00 40 00 00 02 26 01
				39 00 00 40 00 00 06 F0 55 AA 52 08 00
				39 00 00 40 00 00 02 B2 08
				39 00 00 40 00 00 05 51 00 14 01 55
				39 00 00 00 00 00 02 39 00
			];
			mi,mdss-dsi-doze-lbm-command-state = "dsi_lp_mode";

			mi,mdss-dsi-doze-hbm-nolp-command = [
				39 00 00 00 00 00 06 F0 55 AA 52 08 00
				39 00 00 40 00 00 02 B2 18
				39 00 00 40 00 00 05 51 00 F5 0F FE
				39 00 00 00 00 00 02 38 00
			];
			mi,mdss-dsi-doze-hbm-nolp-command-state = "dsi_lp_mode";

			mi,mdss-dsi-doze-lbm-nolp-command = [
				39 00 00 00 00 00 06 F0 55 AA 52 08 00
				39 00 00 40 00 00 02 B2 18
				39 00 00 40 00 00 05 51 00 14 01 55
				39 00 00 00 00 00 02 38 00
			];
			mi,mdss-dsi-doze-lbm-nolp-command-state = "dsi_lp_mode";

			mi,mdss-dsi-local-hbm-normal-white-1000nit-command = [
				39 00 00 00 00 00 06 F0 55 AA 52 08 00
				39 00 00 40 00 00 02 6F 29
				39 00 00 40 00 00 02 D9 00
				39 00 00 40 00 00 02 6F 01
				39 00 00 40 00 00 02 D9 80
				39 00 00 40 00 00 02 6F 07
				39 00 00 40 00 00 03 B2 07 FF
				39 00 00 40 00 00 02 6F 17
				39 00 00 40 00 00 03 B2 07 FF
				39 00 00 40 00 00 02 6F 1F
				39 00 00 40 00 00 03 B2 00 50
				39 00 00 40 00 00 06 F0 55 AA 52 08 02
				39 00 00 40 00 00 02 6F 08
				39 00 00 40 00 00 07 D0 0B 07 09 7B 0C 1D
				39 00 00 40 00 00 06 F0 55 AA 52 08 07
				39 00 00 40 00 00 02 C0 05
				39 00 00 40 00 00 02 53 20
				39 00 00 40 00 00 05 88 02 1C 08 73
				39 00 00 40 00 00 03 51 07 FF
				39 00 00 40 00 00 03 87 04 4E
				39 00 00 40 00 00 02 6F 02
				39 00 00 00 30 00 02 87 05
			];
			mi,mdss-dsi-local-hbm-normal-white-1000nit-command-update = <0x87 19 2>, <0xD0 13 6>;
			mi,mdss-dsi-local-hbm-normal-white-1000nit-command-state = "dsi_hs_mode";

			mi,mdss-dsi-local-hbm-hlpm-white-1000nit-command = [
				/* AOD off */
				39 00 00 00 00 00 06 F0 55 AA 52 08 00
				39 00 00 40 00 00 02 B2 18
				39 00 00 40 00 00 02 38 00
				/* Local HBM setting*/
				39 00 00 40 00 00 06 F0 55 AA 52 08 00
				39 00 00 40 00 00 02 6F 29
				39 00 00 40 00 00 02 D9 00
				39 00 00 40 00 00 02 6F 01
				39 00 00 40 00 00 02 D9 80
				39 00 00 40 00 00 02 6F 07
				39 00 00 40 00 00 03 B2 07 FF
				39 00 00 40 00 00 02 6F 17
				39 00 00 40 00 00 03 B2 07 FF
				39 00 00 40 00 00 02 6F 1F
				39 00 00 40 00 00 03 B2 00 50
				39 00 00 40 00 00 06 F0 55 AA 52 08 02
				39 00 00 40 00 00 02 6F 08
				39 00 00 40 00 00 07 D0 0B 07 09 7B 0C 1D
				39 00 00 40 00 00 06 F0 55 AA 52 08 07
				39 00 00 40 00 00 02 C0 05
				39 00 00 40 00 00 02 53 20
				39 00 00 40 00 00 05 88 02 1C 08 73
				39 00 00 40 00 00 03 51 07 FF
				39 00 00 40 00 00 03 87 04 4E
				39 00 00 40 00 00 02 6F 02
				39 00 00 00 30 00 02 87 05
			];
			mi,mdss-dsi-local-hbm-hlpm-white-1000nit-command-update = <0x87 22 2>, <0xD0 16 6>;
			mi,mdss-dsi-local-hbm-hlpm-white-1000nit-command-state = "dsi_hs_mode";

			mi,mdss-dsi-local-hbm-normal-white-110nit-command = [
				39 00 00 00 00 00 06 F0 55 AA 52 08 00
				39 00 00 40 00 00 02 6F 29
				39 00 00 40 00 00 02 D9 00
				39 00 00 40 00 00 02 6F 01
				39 00 00 40 00 00 02 D9 80
				39 00 00 40 00 00 02 6F 07
				39 00 00 40 00 00 03 B2 07 FF
				39 00 00 40 00 00 02 6F 17
				39 00 00 40 00 00 03 B2 07 FF
				39 00 00 40 00 00 02 6F 1F
				39 00 00 40 00 00 03 B2 00 50
				39 00 00 40 00 00 06 F0 55 AA 52 08 02
				39 00 00 40 00 00 02 6F 08
				39 00 00 40 00 00 07 D0 0B 07 09 7B 0C 1D
				39 00 00 40 00 00 06 F0 55 AA 52 08 07
				39 00 00 40 00 00 02 C0 05
				39 00 00 40 00 00 02 53 20
				39 00 00 40 00 00 05 88 02 1C 08 73
				39 00 00 40 00 00 03 51 07 FF
				39 00 00 40 00 00 03 87 04 4E
				39 00 00 40 00 00 02 6F 02
				39 00 00 00 30 00 02 87 05
			];
			mi,mdss-dsi-local-hbm-normal-white-110nit-command-update = <0x87 19 2>, <0xD0 13 6>;
			mi,mdss-dsi-local-hbm-normal-white-110nit-command-state = "dsi_hs_mode";

			mi,mdss-dsi-local-hbm-hlpm-white-110nit-command = [
				/* AOD off */
				39 00 00 00 00 00 06 F0 55 AA 52 08 00
				39 00 00 40 00 00 02 B2 18
				39 00 00 40 00 00 02 38 00
				/* Local HBM setting*/
				39 00 00 40 00 00 06 F0 55 AA 52 08 00
				39 00 00 40 00 00 02 6F 29
				39 00 00 40 00 00 02 D9 00
				39 00 00 40 00 00 02 6F 01
				39 00 00 40 00 00 02 D9 80
				39 00 00 40 00 00 02 6F 07
				39 00 00 40 00 00 03 B2 07 FF
				39 00 00 40 00 00 02 6F 17
				39 00 00 40 00 00 03 B2 07 FF
				39 00 00 40 00 00 02 6F 1F
				39 00 00 40 00 00 03 B2 00 50
				39 00 00 40 00 00 06 F0 55 AA 52 08 02
				39 00 00 40 00 00 02 6F 08
				39 00 00 40 00 00 07 D0 0B 07 09 7B 0C 1D
				39 00 00 40 00 00 06 F0 55 AA 52 08 07
				39 00 00 40 00 00 02 C0 05
				39 00 00 40 00 00 02 53 20
				39 00 00 40 00 00 05 88 02 1C 08 73
				39 00 00 40 00 00 03 51 07 FF
				39 00 00 40 00 00 03 87 04 4E
				39 00 00 40 00 00 02 6F 02
				39 00 00 00 30 00 02 87 05
			];
			mi,mdss-dsi-local-hbm-hlpm-white-110nit-command-update = <0x87 22 2>, <0xD0 16 6>;
			mi,mdss-dsi-local-hbm-hlpm-white-110nit-command-state = "dsi_hs_mode";

			mi,mdss-dsi-local-hbm-normal-green-500nit-command = [
				39 00 00 00 00 00 06 F0 55 AA 52 08 00
				39 00 00 40 00 00 02 6F 29
				39 00 00 40 00 00 02 D9 00
				39 00 00 40 00 00 02 6F 01
				39 00 00 40 00 00 02 D9 80
				39 00 00 40 00 00 02 6F 07
				39 00 00 40 00 00 03 B2 07 FF
				39 00 00 40 00 00 02 6F 17
				39 00 00 40 00 00 03 B2 07 FF
				39 00 00 40 00 00 02 6F 1F
				39 00 00 40 00 00 03 B2 00 50
				39 00 00 40 00 00 06 F0 55 AA 52 08 02
				39 00 00 40 00 00 02 6F 08
				39 00 00 40 00 00 07 D0 00 00 09 40 00 00
				39 00 00 40 00 00 06 F0 55 AA 52 08 07
				39 00 00 40 00 00 02 C0 05
				39 00 00 40 00 00 02 53 20
				39 00 00 40 00 00 05 88 02 1C 08 73
				39 00 00 40 00 00 03 51 07 FF
				39 00 00 40 00 00 03 87 04 4E
				39 00 00 40 00 00 02 6F 02
				39 00 00 00 30 00 02 87 05
			];
			mi,mdss-dsi-local-hbm-normal-green-500nit-command-update = <0x87 19 2>, <0xD0 13 6>;
			mi,mdss-dsi-local-hbm-normal-green-500nit-command-state = "dsi_hs_mode";

			mi,mdss-dsi-local-hbm-off-to-normal-command = [
				39 00 00 00 00 00 02 53 20
				39 00 00 40 00 00 03 51 00 00
				39 00 00 40 00 00 02 6F 02
				39 00 00 00 00 00 02 87 04
			];
			mi,mdss-dsi-local-hbm-off-to-normal-command-update = <0x51 1 2>;
			mi,mdss-dsi-local-hbm-off-to-normal-command-state = "dsi_hs_mode";

			mi,mdss-dsi-local-hbm-off-to-hbm-command = [
				39 00 00 00 00 00 02 53 20
				39 00 00 40 00 00 03 51 00 00
				39 00 00 40 00 00 02 6F 02
				39 00 00 00 00 00 02 87 04
			];
			mi,mdss-dsi-local-hbm-off-to-hbm-command-update = <0x51 1 2>;
			mi,mdss-dsi-local-hbm-off-to-hbm-command-state = "dsi_hs_mode";

			mi,mdss-dsi-local-hbm-off-to-hlpm-command = [
				/* local hbm off */
				39 00 00 00 00 00 02 53 20
				39 00 00 40 00 00 03 51 00 00
				39 00 00 40 00 00 02 6F 02
				39 00 00 40 00 00 02 87 04
				/* aod hbm */
				39 00 00 40 00 00 02 2F 01
				39 00 00 40 00 00 02 26 01
				39 00 00 40 00 00 06 F0 55 AA 52 08 00
				39 00 00 40 00 00 02 B2 08
				39 00 00 40 00 00 05 51 00 F5 0F FF
				39 00 00 00 00 00 02 39 00
			];
			mi,mdss-dsi-local-hbm-off-to-hlpm-command-state = "dsi_hs_mode";

			mi,mdss-dsi-local-hbm-off-to-llpm-command = [
				/* local hbm off */
				39 00 00 00 00 00 02 53 20
				39 00 00 40 00 00 03 51 00 00
				39 00 00 40 00 00 02 6F 02
				39 00 00 40 00 00 02 87 04
				/* aod lbm */
				39 00 00 40 00 00 02 2F 01
				39 00 00 40 00 00 02 26 01
				39 00 00 40 00 00 06 F0 55 AA 52 08 00
				39 00 00 40 00 00 02 B2 08
				39 00 00 40 00 00 05 51 00 14 01 55
				39 00 00 00 00 00 02 39 00
			];
			mi,mdss-dsi-local-hbm-off-to-llpm-command-state = "dsi_hs_mode";

			mi,mdss-dsi-pre-doze-to-off-command = [
				39 01 00 00 00 00 06 F0 55 AA 52 08 01
				39 01 00 00 00 00 02 CE 0C];
			mi,mdss-dsi-pre-doze-to-off-command-state = "dsi_hs_mode";
		};

		/* 120Hz */
		timing@1{
			mi,mdss-dsc-panel-id = <0x004C3953 0x00420200>;
			/*<flat on gamma, flat off gamma>*/
			mi,mdss-flat-status-control-gamma-cfg = <0x60 0x20>;
			mi,mdss-dsi-dimmingon-command = [39 00 00 00 00 00 02 53 28];
			mi,mdss-dsi-dimmingon-command-state = "dsi_hs_mode";
			mi,mdss-dsi-dimmingoff-command = [39 00 00 00 00 00 02 53 20];
			mi,mdss-dsi-dimmingoff-command-state = "dsi_hs_mode";

			mi,mdss-dsi-hbm-on-command = [39 00 00 00 00 00 05 51 0F FF 00 00];
			mi,mdss-dsi-hbm-on-command-state = "dsi_lp_mode";
			mi,mdss-dsi-hbm-off-command = [39 00 00 00 00 00 05 51 07 FF 00 00];
			mi,mdss-dsi-hbm-off-command-state = "dsi_lp_mode";

			mi,mdss-dsi-switch-page-command = [
			/* switch page, last byte is page config */
				39 00 00 00 00 00 06 F0 55 AA 52 08 00
			];
			/* <mipi_address  update_index  update_length> */
			mi,mdss-dsi-switch-page-command-update = <0xF0 0 5>;
			mi,mdss-dsi-switch-page-command-state = "dsi_lp_mode";

			mi,mdss-dsi-flat-mode-read-pre-command = [
				39 00 00 00 00 00 06 F0 55 AA 52 08 00
				39 00 00 00 00 00 02 6F 3F
			];
			mi,mdss-dsi-flat-mode-read-pre-command-state = "dsi_lp_mode";

			mi,mdss-dsi-flat-mode-off-read-pre-command = [
				39 00 00 00 00 00 06 F0 55 AA 52 08 00
				39 00 00 00 00 00 02 6F 48
			];
			mi,mdss-dsi-flat-mode-off-read-pre-command-state = "dsi_lp_mode";

			mi,mdss-dsi-flat-mode-on-command = [
				/* 120 Hz gir cmd_1,need sync te*/
				39 00 00 00 00 00 02 2F 02
				39 00 00 40 00 00 06 F0 55 AA 52 08 00
				39 00 00 40 00 00 02 6F 09
				39 00 00 40 00 00 02 C0 60
				39 00 00 40 00 00 06 F0 55 AA 52 08 02
				39 00 00 40 00 00 02 CC 30
				39 00 00 40 00 00 02 CE 01
				39 00 00 40 00 00 06 F0 55 AA 52 08 08
				39 00 00 40 00 00 02 6F 07
				39 00 00 20 14 00 05 B9 00 00 00 00
			];
			/* <mipi_address  update_index  update_length> */
			mi,mdss-dsi-flat-mode-on-command-update = <0xB9 9 4>;

			mi,mdss-dsi-flat-mode-on-sec-command = [
				/* 120 Hz gir cmd_2*/
				39 00 00 00 00 00 06 F0 55 AA 52 08 02
				39 00 00 00 00 00 02 CC 00
			];
			mi,mdss-dsi-flat-mode-on-command-state = "dsi_hs_mode";
			mi,mdss-dsi-flat-mode-on-sec-command-state = "dsi_lp_mode";

			mi,mdss-dsi-flat-mode-off-command = [
				/* 120 Hz gir cmd_1,need sync te*/
				39 00 00 00 00 00 02 2F 02
				39 00 00 40 00 00 06 F0 55 AA 52 08 00
				39 00 00 40 00 00 02 6F 09
				39 00 00 40 00 00 02 C0 20
				39 00 00 40 00 00 06 F0 55 AA 52 08 02
				39 00 00 40 00 00 02 CC 30
				39 00 00 40 00 00 02 CE 01
				39 00 00 40 00 00 06 F0 55 AA 52 08 08
				39 00 00 40 00 00 02 6F 07
				39 00 00 20 14 00 05 B9 00 00 00 18
			];
			/* <mipi_address  update_index  update_length> */
			mi,mdss-dsi-flat-mode-off-command-update = <0xB9 9 4>;
			mi,mdss-dsi-flat-mode-off-sec-command = [
				/* 120 Hz gir cmd_2*/
				39 00 00 00 00 00 06 F0 55 AA 52 08 02
				39 00 00 00 00 00 02 CC 00
			];
			mi,mdss-dsi-flat-mode-off-command-state = "dsi_hs_mode";
			mi,mdss-dsi-flat-mode-off-sec-command-state = "dsi_lp_mode";

			mi,mdss-dsi-doze-hbm-command = [
				39 00 00 00 00 00 02 2F 01
				39 00 00 40 00 00 02 26 01
				39 00 00 40 00 00 06 F0 55 AA 52 08 00
				39 00 00 40 00 00 02 B2 08
				39 00 00 40 00 00 05 51 00 F5 0F FE
				39 00 00 00 00 00 02 39 00
			];
			mi,mdss-dsi-doze-hbm-command-state = "dsi_lp_mode";

			mi,mdss-dsi-doze-lbm-command = [
				39 00 00 00 00 00 02 2F 01
				39 00 00 40 00 00 02 26 01
				39 00 00 40 00 00 06 F0 55 AA 52 08 00
				39 00 00 40 00 00 02 B2 08
				39 00 00 40 00 00 05 51 00 14 01 55
				39 00 00 00 00 00 02 39 00
			];
			mi,mdss-dsi-doze-lbm-command-state = "dsi_lp_mode";

			mi,mdss-dsi-doze-hbm-nolp-command = [
				39 00 00 00 00 00 06 F0 55 AA 52 08 00
				39 00 00 40 00 00 02 B2 18
				39 00 00 40 00 00 05 51 00 F5 0F FE
				39 00 00 00 00 00 02 38 00
				39 00 00 00 00 00 02 2F 02
			];
			mi,mdss-dsi-doze-hbm-nolp-command-state = "dsi_lp_mode";

			mi,mdss-dsi-doze-lbm-nolp-command = [
				39 00 00 00 00 00 06 F0 55 AA 52 08 00
				39 00 00 40 00 00 02 B2 18
				39 00 00 40 00 00 05 51 00 14 01 55
				39 00 00 00 00 00 02 38 00
				39 00 00 00 00 00 02 2F 02
			];
			mi,mdss-dsi-doze-lbm-nolp-command-state = "dsi_lp_mode";

			mi,mdss-dsi-local-hbm-normal-white-1000nit-command = [
				39 00 00 00 00 00 06 F0 55 AA 52 08 00
				39 00 00 40 00 00 02 6F 29
				39 00 00 40 00 00 02 D9 00
				39 00 00 40 00 00 02 6F 01
				39 00 00 40 00 00 02 D9 80
				39 00 00 40 00 00 02 6F 07
				39 00 00 40 00 00 03 B2 07 FF
				39 00 00 40 00 00 02 6F 17
				39 00 00 40 00 00 03 B2 07 FF
				39 00 00 40 00 00 02 6F 1F
				39 00 00 40 00 00 03 B2 00 50
				39 00 00 40 00 00 06 F0 55 AA 52 08 02
				39 00 00 40 00 00 02 6F 08
				39 00 00 40 00 00 07 D0 0B 07 09 7B 0C 1D
				39 00 00 40 00 00 06 F0 55 AA 52 08 07
				39 00 00 40 00 00 02 C0 05
				39 00 00 40 00 00 02 53 20
				39 00 00 40 00 00 05 88 02 1C 08 73
				39 00 00 40 00 00 03 51 07 FF
				39 00 00 40 00 00 03 87 04 4E
				39 00 00 40 00 00 02 6F 02
				39 00 00 00 30 00 02 87 05
			];
			mi,mdss-dsi-local-hbm-normal-white-1000nit-command-update = <0x87 19 2>, <0xD0 13 6>;
			mi,mdss-dsi-local-hbm-normal-white-1000nit-command-state = "dsi_hs_mode";

			mi,mdss-dsi-local-hbm-hlpm-white-1000nit-command = [
				/* AOD off */
				39 00 00 00 00 00 06 F0 55 AA 52 08 00
				39 00 00 40 00 00 02 B2 18
				39 00 00 40 00 00 02 38 00
				39 00 00 00 00 00 02 2F 02
				/* Local HBM setting*/
				39 00 00 40 00 00 06 F0 55 AA 52 08 00
				39 00 00 40 00 00 02 6F 29
				39 00 00 40 00 00 02 D9 00
				39 00 00 40 00 00 02 6F 01
				39 00 00 40 00 00 02 D9 80
				39 00 00 40 00 00 02 6F 07
				39 00 00 40 00 00 03 B2 07 FF
				39 00 00 40 00 00 02 6F 17
				39 00 00 40 00 00 03 B2 07 FF
				39 00 00 40 00 00 02 6F 1F
				39 00 00 40 00 00 03 B2 00 50
				39 00 00 40 00 00 06 F0 55 AA 52 08 02
				39 00 00 40 00 00 02 6F 08
				39 00 00 40 00 00 07 D0 0B 07 09 7B 0C 1D
				39 00 00 40 00 00 06 F0 55 AA 52 08 07
				39 00 00 40 00 00 02 C0 05
				39 00 00 40 00 00 02 53 20
				39 00 00 40 00 00 05 88 02 1C 08 73
				39 00 00 40 00 00 03 51 07 FF
				39 00 00 40 00 00 03 87 04 4E
				39 00 00 40 00 00 02 6F 02
				39 00 00 00 30 00 02 87 05
			];
			mi,mdss-dsi-local-hbm-hlpm-white-1000nit-command-update = <0x87 23 2>, <0xD0 17 6>;
			mi,mdss-dsi-local-hbm-hlpm-white-1000nit-command-state = "dsi_hs_mode";

			mi,mdss-dsi-local-hbm-normal-white-110nit-command = [
				39 00 00 00 00 00 06 F0 55 AA 52 08 00
				39 00 00 40 00 00 02 6F 29
				39 00 00 40 00 00 02 D9 00
				39 00 00 40 00 00 02 6F 01
				39 00 00 40 00 00 02 D9 80
				39 00 00 40 00 00 02 6F 07
				39 00 00 40 00 00 03 B2 07 FF
				39 00 00 40 00 00 02 6F 17
				39 00 00 40 00 00 03 B2 07 FF
				39 00 00 40 00 00 02 6F 1F
				39 00 00 40 00 00 03 B2 00 50
				39 00 00 40 00 00 06 F0 55 AA 52 08 02
				39 00 00 40 00 00 02 6F 08
				39 00 00 40 00 00 07 D0 0B 07 09 7B 0C 1D
				39 00 00 40 00 00 06 F0 55 AA 52 08 07
				39 00 00 40 00 00 02 C0 05
				39 00 00 40 00 00 02 53 20
				39 00 00 40 00 00 05 88 02 1C 08 73
				39 00 00 40 00 00 03 51 07 FF
				39 00 00 40 00 00 03 87 04 4E
				39 00 00 40 00 00 02 6F 02
				39 00 00 00 30 00 02 87 05
			];
			mi,mdss-dsi-local-hbm-normal-white-110nit-command-update = <0x87 19 2>, <0xD0 13 6>;
			mi,mdss-dsi-local-hbm-normal-white-110nit-command-state = "dsi_hs_mode";

			mi,mdss-dsi-local-hbm-hlpm-white-110nit-command = [
				/* AOD off */
				39 00 00 00 00 00 06 F0 55 AA 52 08 00
				39 00 00 40 00 00 02 B2 18
				39 00 00 40 00 00 02 38 00
				39 00 00 00 00 00 02 2F 02
				/* Local HBM setting*/
				39 00 00 40 00 00 06 F0 55 AA 52 08 00
				39 00 00 40 00 00 02 6F 29
				39 00 00 40 00 00 02 D9 00
				39 00 00 40 00 00 02 6F 01
				39 00 00 40 00 00 02 D9 80
				39 00 00 40 00 00 02 6F 07
				39 00 00 40 00 00 03 B2 07 FF
				39 00 00 40 00 00 02 6F 17
				39 00 00 40 00 00 03 B2 07 FF
				39 00 00 40 00 00 02 6F 1F
				39 00 00 40 00 00 03 B2 00 50
				39 00 00 40 00 00 06 F0 55 AA 52 08 02
				39 00 00 40 00 00 02 6F 08
				39 00 00 40 00 00 07 D0 0B 07 09 7B 0C 1D
				39 00 00 40 00 00 06 F0 55 AA 52 08 07
				39 00 00 40 00 00 02 C0 05
				39 00 00 40 00 00 02 53 20
				39 00 00 40 00 00 05 88 02 1C 08 73
				39 00 00 40 00 00 03 51 07 FF
				39 00 00 40 00 00 03 87 04 4E
				39 00 00 40 00 00 02 6F 02
				39 00 00 00 30 00 02 87 05
			];
			mi,mdss-dsi-local-hbm-hlpm-white-110nit-command-update = <0x87 23 2>, <0xD0 17 6>;
			mi,mdss-dsi-local-hbm-hlpm-white-110nit-command-state = "dsi_hs_mode";

			mi,mdss-dsi-local-hbm-normal-green-500nit-command = [
				39 00 00 00 00 00 06 F0 55 AA 52 08 00
				39 00 00 40 00 00 02 6F 29
				39 00 00 40 00 00 02 D9 00
				39 00 00 40 00 00 02 6F 01
				39 00 00 40 00 00 02 D9 80
				39 00 00 40 00 00 02 6F 07
				39 00 00 40 00 00 03 B2 07 FF
				39 00 00 40 00 00 02 6F 17
				39 00 00 40 00 00 03 B2 07 FF
				39 00 00 40 00 00 02 6F 1F
				39 00 00 40 00 00 03 B2 00 50
				39 00 00 40 00 00 06 F0 55 AA 52 08 02
				39 00 00 40 00 00 02 6F 08
				39 00 00 40 00 00 07 D0 00 00 09 40 00 00
				39 00 00 40 00 00 06 F0 55 AA 52 08 07
				39 00 00 40 00 00 02 C0 05
				39 00 00 40 00 00 02 53 20
				39 00 00 40 00 00 05 88 02 1C 08 73
				39 00 00 40 00 00 03 51 07 FF
				39 00 00 40 00 00 03 87 04 4E
				39 00 00 40 00 00 02 6F 02
				39 00 00 00 30 00 02 87 05
			];
			mi,mdss-dsi-local-hbm-normal-green-500nit-command-update = <0x87 19 2>, <0xD0 13 6>;
			mi,mdss-dsi-local-hbm-normal-green-500nit-command-state = "dsi_hs_mode";

			mi,mdss-dsi-local-hbm-off-to-normal-command = [
				39 00 00 00 00 00 02 53 20
				39 00 00 40 00 00 03 51 00 00
				39 00 00 40 00 00 02 6F 02
				39 00 00 00 00 00 02 87 04
			];
			mi,mdss-dsi-local-hbm-off-to-normal-command-update = <0x51 1 2>;
			mi,mdss-dsi-local-hbm-off-to-normal-command-state = "dsi_hs_mode";

			mi,mdss-dsi-local-hbm-off-to-hbm-command = [
				39 00 00 00 00 00 02 53 20
				39 00 00 40 00 00 03 51 00 00
				39 00 00 40 00 00 02 6F 02
				39 00 00 00 00 00 02 87 04
			];
			mi,mdss-dsi-local-hbm-off-to-hbm-command-update = <0x51 1 2>;
			mi,mdss-dsi-local-hbm-off-to-hbm-command-state = "dsi_hs_mode";

			mi,mdss-dsi-local-hbm-off-to-hlpm-command = [
				/* local hbm off */
				39 00 00 00 00 00 02 53 20
				39 00 00 40 00 00 03 51 00 00
				39 00 00 40 00 00 02 6F 02
				39 00 00 40 00 00 02 87 04
				/* aod hbm */
				39 00 00 40 00 00 02 2F 01
				39 00 00 40 00 00 02 26 01
				39 00 00 40 00 00 06 F0 55 AA 52 08 00
				39 00 00 40 00 00 02 B2 08
				39 00 00 40 00 00 05 51 00 F5 0F FF
				39 00 00 00 00 00 02 39 00
			];
			mi,mdss-dsi-local-hbm-off-to-hlpm-command-state = "dsi_hs_mode";

			mi,mdss-dsi-local-hbm-off-to-llpm-command = [
				/* local hbm off */
				39 00 00 00 00 00 02 53 20
				39 00 00 40 00 00 03 51 00 00
				39 00 00 40 00 00 02 6F 02
				39 00 00 40 00 00 02 87 04
				/* aod lbm */
				39 00 00 40 00 00 02 2F 01
				39 00 00 40 00 00 02 26 01
				39 00 00 40 00 00 06 F0 55 AA 52 08 00
				39 00 00 40 00 00 02 B2 08
				39 00 00 40 00 00 05 51 00 14 01 55
				39 00 00 00 00 00 02 39 00
			];
			mi,mdss-dsi-local-hbm-off-to-llpm-command-state = "dsi_hs_mode";

			mi,mdss-dsi-pre-doze-to-off-command = [
				39 01 00 00 00 00 06 F0 55 AA 52 08 01
				39 01 00 00 00 00 02 CE 0C];
			mi,mdss-dsi-pre-doze-to-off-command-state = "dsi_hs_mode";
		};

		/* 90Hz */
		timing@2{
			mi,mdss-dsc-panel-id = <0x004C3953 0x00420200>;
			/*<flat on gamma, flat off gamma>*/
			mi,mdss-flat-status-control-gamma-cfg = <0x60 0x20>;
			mi,mdss-dsi-dimmingon-command = [39 00 00 00 00 00 02 53 28];
			mi,mdss-dsi-dimmingon-command-state = "dsi_hs_mode";
			mi,mdss-dsi-dimmingoff-command = [39 00 00 00 00 00 02 53 20];
			mi,mdss-dsi-dimmingoff-command-state = "dsi_hs_mode";

			mi,mdss-dsi-hbm-on-command = [39 00 00 00 00 00 05 51 0F FF 00 00];
			mi,mdss-dsi-hbm-on-command-state = "dsi_lp_mode";
			mi,mdss-dsi-hbm-off-command = [39 00 00 00 00 00 05 51 07 FF 00 00];
			mi,mdss-dsi-hbm-off-command-state = "dsi_lp_mode";

			mi,mdss-dsi-switch-page-command = [
			/* switch page, last byte is page config */
				39 00 00 00 00 00 06 F0 55 AA 52 08 00
			];
			/* <mipi_address  update_index  update_length> */
			mi,mdss-dsi-switch-page-command-update = <0xF0 0 5>;
			mi,mdss-dsi-switch-page-command-state = "dsi_lp_mode";

			mi,mdss-dsi-flat-mode-read-pre-command = [
				39 00 00 00 00 00 06 F0 55 AA 52 08 00
				39 00 00 00 00 00 02 6F 3F
			];
			mi,mdss-dsi-flat-mode-read-pre-command-state = "dsi_lp_mode";

			mi,mdss-dsi-flat-mode-off-read-pre-command = [
				39 00 00 00 00 00 06 F0 55 AA 52 08 00
				39 00 00 00 00 00 02 6F 48
			];
			mi,mdss-dsi-flat-mode-off-read-pre-command-state = "dsi_lp_mode";

			mi,mdss-dsi-flat-mode-on-command = [
				/* 90 Hz gir cmd_1,need sync te*/
				39 00 00 00 00 00 02 2F 03
				39 00 00 40 00 00 06 F0 55 AA 52 08 00
				39 00 00 40 00 00 02 6F 0A
				39 00 00 40 00 00 02 C0 60
				39 00 00 40 00 00 06 F0 55 AA 52 08 02
				39 00 00 40 00 00 02 CC 30
				39 00 00 40 00 00 02 CE 01
				39 00 00 40 00 00 06 F0 55 AA 52 08 08
				39 00 00 40 00 00 02 6F 07
				39 00 00 20 14 00 05 B9 00 00 00 00
			];
			/* <mipi_address  update_index  update_length> */
			mi,mdss-dsi-flat-mode-on-command-update = <0xB9 9 4>;

			mi,mdss-dsi-flat-mode-on-sec-command = [
				/* 90 Hz gir cmd_2*/
				39 00 00 00 00 00 06 F0 55 AA 52 08 02
				39 00 00 00 00 00 02 CC 00
			];
			mi,mdss-dsi-flat-mode-on-command-state = "dsi_lp_mode";
			mi,mdss-dsi-flat-mode-on-sec-command-state = "dsi_lp_mode";

			mi,mdss-dsi-flat-mode-off-command = [
				/* 90 Hz gir cmd_1,need sync te*/
				39 00 00 00 00 00 02 2F 03
				39 00 00 40 00 00 06 F0 55 AA 52 08 00
				39 00 00 40 00 00 02 6F 0A
				39 00 00 40 00 00 02 C0 20
				39 00 00 40 00 00 06 F0 55 AA 52 08 02
				39 00 00 40 00 00 02 CC 30
				39 00 00 40 00 00 02 CE 01
				39 00 00 40 00 00 06 F0 55 AA 52 08 08
				39 00 00 40 00 00 02 6F 07
				39 00 00 20 14 00 05 B9 00 00 00 18
			];
			/* <mipi_address  update_index  update_length> */
			mi,mdss-dsi-flat-mode-off-command-update = <0xB9 9 4>;
			mi,mdss-dsi-flat-mode-off-sec-command = [
				/* 90 Hz gir cmd_2*/
				39 00 00 00 00 00 06 F0 55 AA 52 08 02
				39 00 00 00 00 00 02 CC 00
			];
			mi,mdss-dsi-flat-mode-off-command-state = "dsi_lp_mode";
			mi,mdss-dsi-flat-mode-off-sec-command-state = "dsi_lp_mode";

			mi,mdss-dsi-doze-hbm-command = [
				39 00 00 00 00 00 02 2F 01
				39 00 00 40 00 00 02 26 01
				39 00 00 40 00 00 06 F0 55 AA 52 08 00
				39 00 00 40 00 00 02 B2 08
				39 00 00 40 00 00 05 51 00 F5 0F FE
				39 00 00 00 00 00 02 39 00
			];
			mi,mdss-dsi-doze-hbm-command-state = "dsi_lp_mode";

			mi,mdss-dsi-doze-lbm-command = [
				39 00 00 00 00 00 02 2F 01
				39 00 00 40 00 00 02 26 01
				39 00 00 40 00 00 06 F0 55 AA 52 08 00
				39 00 00 40 00 00 02 B2 08
				39 00 00 40 00 00 05 51 00 14 01 55
				39 00 00 00 00 00 02 39 00
			];
			mi,mdss-dsi-doze-lbm-command-state = "dsi_lp_mode";

			mi,mdss-dsi-doze-hbm-nolp-command = [
				39 00 00 00 00 00 06 F0 55 AA 52 08 00
				39 00 00 40 00 00 02 B2 18
				39 00 00 40 00 00 05 51 00 F5 0F FE
				39 00 00 00 00 00 02 38 00
			];
			mi,mdss-dsi-doze-hbm-nolp-command-state = "dsi_lp_mode";

			mi,mdss-dsi-doze-lbm-nolp-command = [
				39 00 00 00 00 00 06 F0 55 AA 52 08 00
				39 00 00 40 00 00 02 B2 18
				39 00 00 40 00 00 05 51 00 14 01 55
				39 00 00 00 00 00 02 38 00
			];
			mi,mdss-dsi-doze-lbm-nolp-command-state = "dsi_lp_mode";

			mi,mdss-dsi-local-hbm-normal-white-1000nit-command = [
				39 00 00 00 00 00 06 F0 55 AA 52 08 00
				39 00 00 40 00 00 02 6F 29
				39 00 00 40 00 00 02 D9 00
				39 00 00 40 00 00 02 6F 01
				39 00 00 40 00 00 02 D9 80
				39 00 00 40 00 00 02 6F 07
				39 00 00 40 00 00 03 B2 07 FF
				39 00 00 40 00 00 02 6F 17
				39 00 00 40 00 00 03 B2 07 FF
				39 00 00 40 00 00 02 6F 1F
				39 00 00 40 00 00 03 B2 00 50
				39 00 00 40 00 00 06 F0 55 AA 52 08 02
				39 00 00 40 00 00 02 6F 08
				39 00 00 40 00 00 07 D0 0B 07 09 7B 0C 1D
				39 00 00 40 00 00 06 F0 55 AA 52 08 07
				39 00 00 40 00 00 02 C0 05
				39 00 00 40 00 00 02 53 20
				39 00 00 40 00 00 05 88 02 1C 08 73
				39 00 00 40 00 00 03 51 07 FF
				39 00 00 40 00 00 03 87 04 4E
				39 00 00 40 00 00 02 6F 02
				39 00 00 00 30 00 02 87 05
			];
			mi,mdss-dsi-local-hbm-normal-white-1000nit-command-update = <0x87 19 2>, <0xD0 13 6>;
			mi,mdss-dsi-local-hbm-normal-white-1000nit-command-state = "dsi_hs_mode";

			mi,mdss-dsi-local-hbm-hlpm-white-1000nit-command = [
				/* AOD off */
				39 00 00 00 00 00 06 F0 55 AA 52 08 00
				39 00 00 40 00 00 02 B2 18
				39 00 00 40 00 00 02 38 00
				/* Local HBM setting*/
				39 00 00 40 00 00 06 F0 55 AA 52 08 00
				39 00 00 40 00 00 02 6F 29
				39 00 00 40 00 00 02 D9 00
				39 00 00 40 00 00 02 6F 01
				39 00 00 40 00 00 02 D9 80
				39 00 00 40 00 00 02 6F 07
				39 00 00 40 00 00 03 B2 07 FF
				39 00 00 40 00 00 02 6F 17
				39 00 00 40 00 00 03 B2 07 FF
				39 00 00 40 00 00 02 6F 1F
				39 00 00 40 00 00 03 B2 00 50
				39 00 00 40 00 00 06 F0 55 AA 52 08 02
				39 00 00 40 00 00 02 6F 08
				39 00 00 40 00 00 07 D0 0B 07 09 7B 0C 1D
				39 00 00 40 00 00 06 F0 55 AA 52 08 07
				39 00 00 40 00 00 02 C0 05
				39 00 00 40 00 00 02 53 20
				39 00 00 40 00 00 05 88 02 1C 08 73
				39 00 00 40 00 00 03 51 07 FF
				39 00 00 40 00 00 03 87 04 4E
				39 00 00 40 00 00 02 6F 02
				39 00 00 00 30 00 02 87 05
			];
			mi,mdss-dsi-local-hbm-hlpm-white-1000nit-command-update = <0x87 22 2>, <0xD0 16 6>;
			mi,mdss-dsi-local-hbm-hlpm-white-1000nit-command-state = "dsi_hs_mode";

			mi,mdss-dsi-local-hbm-normal-white-110nit-command = [
				39 00 00 00 00 00 06 F0 55 AA 52 08 00
				39 00 00 40 00 00 02 6F 29
				39 00 00 40 00 00 02 D9 00
				39 00 00 40 00 00 02 6F 01
				39 00 00 40 00 00 02 D9 80
				39 00 00 40 00 00 02 6F 07
				39 00 00 40 00 00 03 B2 07 FF
				39 00 00 40 00 00 02 6F 17
				39 00 00 40 00 00 03 B2 07 FF
				39 00 00 40 00 00 02 6F 1F
				39 00 00 40 00 00 03 B2 00 50
				39 00 00 40 00 00 06 F0 55 AA 52 08 02
				39 00 00 40 00 00 02 6F 08
				39 00 00 40 00 00 07 D0 0B 07 09 7B 0C 1D
				39 00 00 40 00 00 06 F0 55 AA 52 08 07
				39 00 00 40 00 00 02 C0 05
				39 00 00 40 00 00 02 53 20
				39 00 00 40 00 00 05 88 02 1C 08 73
				39 00 00 40 00 00 03 51 07 FF
				39 00 00 40 00 00 03 87 04 4E
				39 00 00 40 00 00 02 6F 02
				39 00 00 00 30 00 02 87 05
			];
			mi,mdss-dsi-local-hbm-normal-white-110nit-command-update = <0x87 19 2>, <0xD0 13 6>;
			mi,mdss-dsi-local-hbm-normal-white-110nit-command-state = "dsi_hs_mode";

			mi,mdss-dsi-local-hbm-hlpm-white-110nit-command = [
				/* AOD off */
				39 00 00 00 00 00 06 F0 55 AA 52 08 00
				39 00 00 40 00 00 02 B2 18
				39 00 00 40 00 00 02 38 00
				/* Local HBM setting*/
				39 00 00 40 00 00 06 F0 55 AA 52 08 00
				39 00 00 40 00 00 02 6F 29
				39 00 00 40 00 00 02 D9 00
				39 00 00 40 00 00 02 6F 01
				39 00 00 40 00 00 02 D9 80
				39 00 00 40 00 00 02 6F 07
				39 00 00 40 00 00 03 B2 07 FF
				39 00 00 40 00 00 02 6F 17
				39 00 00 40 00 00 03 B2 07 FF
				39 00 00 40 00 00 02 6F 1F
				39 00 00 40 00 00 03 B2 00 50
				39 00 00 40 00 00 06 F0 55 AA 52 08 02
				39 00 00 40 00 00 02 6F 08
				39 00 00 40 00 00 07 D0 0B 07 09 7B 0C 1D
				39 00 00 40 00 00 06 F0 55 AA 52 08 07
				39 00 00 40 00 00 02 C0 05
				39 00 00 40 00 00 02 53 20
				39 00 00 40 00 00 05 88 02 1C 08 73
				39 00 00 40 00 00 03 51 07 FF
				39 00 00 40 00 00 03 87 04 4E
				39 00 00 40 00 00 02 6F 02
				39 00 00 00 30 00 02 87 05
			];
			mi,mdss-dsi-local-hbm-hlpm-white-110nit-command-update = <0x87 22 2>, <0xD0 16 6>;
			mi,mdss-dsi-local-hbm-hlpm-white-110nit-command-state = "dsi_hs_mode";

			mi,mdss-dsi-local-hbm-normal-green-500nit-command = [
				39 00 00 00 00 00 06 F0 55 AA 52 08 00
				39 00 00 40 00 00 02 6F 29
				39 00 00 40 00 00 02 D9 00
				39 00 00 40 00 00 02 6F 01
				39 00 00 40 00 00 02 D9 80
				39 00 00 40 00 00 02 6F 07
				39 00 00 40 00 00 03 B2 07 FF
				39 00 00 40 00 00 02 6F 17
				39 00 00 40 00 00 03 B2 07 FF
				39 00 00 40 00 00 02 6F 1F
				39 00 00 40 00 00 03 B2 00 50
				39 00 00 40 00 00 06 F0 55 AA 52 08 02
				39 00 00 40 00 00 02 6F 08
				39 00 00 40 00 00 07 D0 00 00 09 40 00 00
				39 00 00 40 00 00 06 F0 55 AA 52 08 07
				39 00 00 40 00 00 02 C0 05
				39 00 00 40 00 00 02 53 20
				39 00 00 40 00 00 05 88 02 1C 08 73
				39 00 00 40 00 00 03 51 07 FF
				39 00 00 40 00 00 03 87 04 4E
				39 00 00 40 00 00 02 6F 02
				39 00 00 00 30 00 02 87 05
			];
			mi,mdss-dsi-local-hbm-normal-green-500nit-command-update = <0x87 19 2>, <0xD0 13 6>;
			mi,mdss-dsi-local-hbm-normal-green-500nit-command-state = "dsi_hs_mode";

			mi,mdss-dsi-local-hbm-off-to-normal-command = [
				39 00 00 00 00 00 02 53 20
				39 00 00 40 00 00 03 51 00 00
				39 00 00 40 00 00 02 6F 02
				39 00 00 00 00 00 02 87 04
			];
			mi,mdss-dsi-local-hbm-off-to-normal-command-update = <0x51 1 2>;
			mi,mdss-dsi-local-hbm-off-to-normal-command-state = "dsi_hs_mode";

			mi,mdss-dsi-local-hbm-off-to-hbm-command = [
				39 00 00 00 00 00 02 53 20
				39 00 00 40 00 00 03 51 00 00
				39 00 00 40 00 00 02 6F 02
				39 00 00 00 00 00 02 87 04
			];
			mi,mdss-dsi-local-hbm-off-to-hbm-command-update = <0x51 1 2>;
			mi,mdss-dsi-local-hbm-off-to-hbm-command-state = "dsi_hs_mode";

			mi,mdss-dsi-local-hbm-off-to-hlpm-command = [
				/* local hbm off */
				39 00 00 00 00 00 02 53 20
				39 00 00 40 00 00 03 51 00 00
				39 00 00 40 00 00 02 6F 02
				39 00 00 40 00 00 02 87 04
				/* aod hbm */
				39 00 00 40 00 00 02 2F 01
				39 00 00 40 00 00 02 26 01
				39 00 00 40 00 00 06 F0 55 AA 52 08 00
				39 00 00 40 00 00 02 B2 08
				39 00 00 40 00 00 05 51 00 F5 0F FF
				39 00 00 00 00 00 02 39 00
			];
			mi,mdss-dsi-local-hbm-off-to-hlpm-command-state = "dsi_hs_mode";

			mi,mdss-dsi-local-hbm-off-to-llpm-command = [
				/* local hbm off */
				39 00 00 00 00 00 02 53 20
				39 00 00 40 00 00 03 51 00 00
				39 00 00 40 00 00 02 6F 02
				39 00 00 40 00 00 02 87 04
				/* aod lbm */
				39 00 00 40 00 00 02 2F 01
				39 00 00 40 00 00 02 26 01
				39 00 00 40 00 00 06 F0 55 AA 52 08 00
				39 00 00 40 00 00 02 B2 08
				39 00 00 40 00 00 05 51 00 14 01 55
				39 00 00 00 00 00 02 39 00
			];
			mi,mdss-dsi-local-hbm-off-to-llpm-command-state = "dsi_hs_mode";

			mi,mdss-dsi-pre-doze-to-off-command = [
				39 01 00 00 00 00 06 F0 55 AA 52 08 01
				39 01 00 00 00 00 02 CE 0C];
			mi,mdss-dsi-pre-doze-to-off-command-state = "dsi_hs_mode";
		};
	};
};
